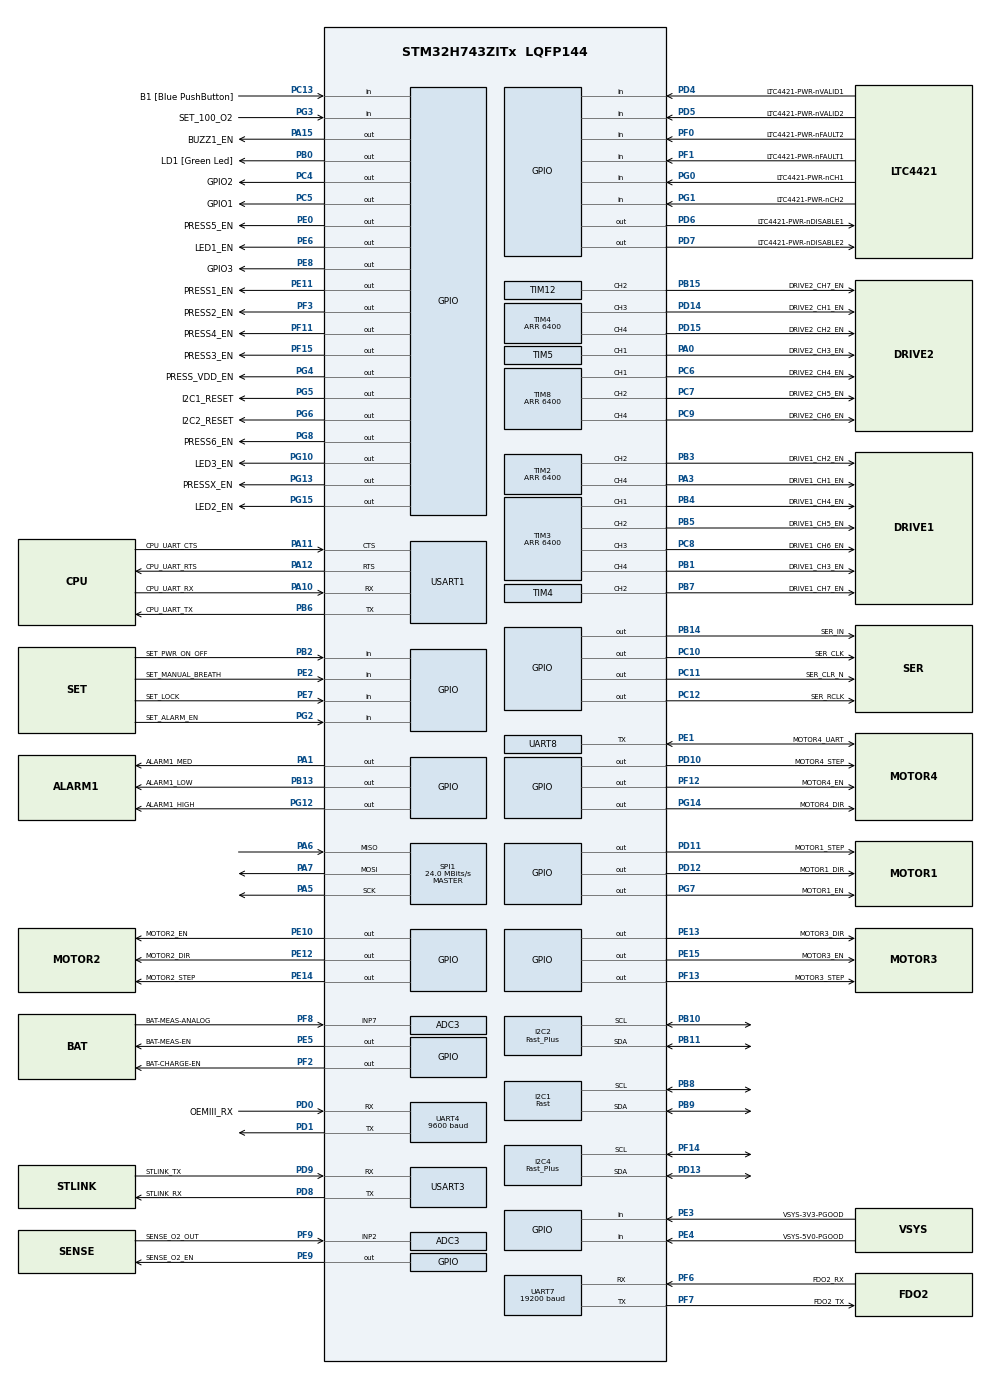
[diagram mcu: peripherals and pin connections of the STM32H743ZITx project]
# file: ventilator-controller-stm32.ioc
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ADC3.Channel-0\#ChannelRegularConversion=ADC_CHANNEL_7
ADC3.ContinuousConvMode=ENABLE
ADC3.EnableAnalogWatchDog3=false
ADC3.NbrOfConversionFlag=1
ADC3.OffsetNumber-0\#ChannelRegularConversion=ADC_OFFSET_NONE
ADC3.Overrun=ADC_OVR_DATA_OVERWRITTEN
ADC3.Rank-0\#ChannelRegularConversion=1
ADC3.SamplingTime-0\#ChannelRegularConversion=ADC_SAMPLETIME_1CYCLE_5
CRC.DefaultPolynomialUse=DEFAULT_POLYNOMIAL_DISABLE
CRC.GeneratingPolynomial=X28+X27+X26+X25+X23+X22+X20+X19+X18+X14+X13+X11+X10+X9+X8+X6+X0
CRC.InputDataInversionMode=CRC_INPUTDATA_INVERSION_BYTE
CRC.OutputDataInversionMode=CRC_OUTPUTDATA_INVERSION_ENABLE
I2C1.I2C_Speed_Mode=I2C_Fast
I2C1.Timing=0x00602173
I2C2.I2C_Speed_Mode=I2C_Fast_Plus
I2C2.Timing=0x00300B29
I2C4.I2C_Speed_Mode=I2C_Fast_Plus
I2C4.Timing=0x00300B29
Mcu.Family=STM32H7
Mcu.Name=STM32H743ZITx
Mcu.Package=LQFP144
NVIC.PriorityGroup=NVIC_PRIORITYGROUP_4
NVIC.UART4_IRQn=true\:0\:0\:false\:false\:true\:true\:true
NVIC.UART7_IRQn=true\:0\:0\:false\:false\:true\:true\:true
NVIC.USART3_IRQn=true\:0\:0\:false\:false\:true\:true\:true
PA0.GPIO_Label=DRIVE2_CH3_EN
PA0.Signal=S_TIM5_CH1
PA1.GPIO_Label=ALARM1_MED
PA1.Signal=GPIO_Output
PA10.GPIO_Label=CPU_UART_RX
PA10.Mode=Asynchronous
PA10.Signal=USART1_RX
PA11.GPIO_Label=CPU_UART_CTS
PA11.Mode=CTS_RTS
PA11.Signal=USART1_CTS
PA12.GPIO_Label=CPU_UART_RTS
PA12.Mode=CTS_RTS
PA12.Signal=USART1_RTS
PA15\ (JTDI).GPIO_Label=BUZZ1_EN
PA15\ (JTDI).Signal=GPIO_Output
PA3.GPIO_Label=DRIVE1_CH1_EN
PA3.Signal=S_TIM2_CH4
PA4.Signal=SPI1_NSS
PA5.Mode=Full_Duplex_Master
PA5.Signal=SPI1_SCK
PA6.Mode=Full_Duplex_Master
PA6.Signal=SPI1_MISO
PA7.Mode=Full_Duplex_Master
PA7.Signal=SPI1_MOSI
PA8.GPIO_Label=CPU_UART_CLK
PA8.Signal=USART1_CK
PB0.GPIO_Label=LD1 [Green Led]
PB0.Signal=GPIO_Output
PB1.GPIO_Label=DRIVE1_CH3_EN
PB1.Signal=S_TIM3_CH4
PB10.Mode=I2C
PB10.Signal=I2C2_SCL
PB11.Mode=I2C
PB11.Signal=I2C2_SDA
PB12.Signal=I2C2_SMBA
PB13.GPIO_Label=ALARM1_LOW
PB13.Signal=GPIO_Output
PB14.GPIO_Label=SER_IN
PB14.Signal=GPIO_Output
PB15.GPIO_Label=DRIVE2_CH7_EN
PB15.Signal=S_TIM12_CH2
PB2.GPIO_Label=SET_PWR_ON_OFF
PB2.Signal=GPIO_Input
PB3\ (JTDO/TRACESWO).GPIO_Label=DRIVE1_CH2_EN
PB3\ (JTDO/TRACESWO).Signal=S_TIM2_CH2
PB4\ (NJTRST).GPIO_Label=DRIVE1_CH4_EN
PB4\ (NJTRST).Signal=S_TIM3_CH1
PB5.GPIO_Label=DRIVE1_CH5_EN
PB5.Signal=S_TIM3_CH2
PB6.GPIO_Label=CPU_UART_TX
PB6.Mode=Asynchronous
PB6.Signal=USART1_TX
PB7.GPIO_Label=DRIVE1_CH7_EN
PB7.Signal=S_TIM4_CH2
PB8.Mode=I2C
PB8.Signal=I2C1_SCL
PB9.Mode=I2C
PB9.Signal=I2C1_SDA
PC10.GPIO_Label=SER_CLK
PC10.Signal=GPIO_Output
PC11.GPIO_Label=SER_CLR_N
PC11.Signal=GPIO_Output
PC12.GPIO_Label=SER_RCLK
PC12.Signal=GPIO_Output
PC13.GPIO_Label=B1 [Blue PushButton]
PC13.Signal=GPIO_Input
PC14-OSC32_IN\ (OSC32_IN).Mode=LSE-External-Oscillator
PC14-OSC32_IN\ (OSC32_IN).Signal=RCC_OSC32_IN
PC15-OSC32_OUT\ (OSC32_OUT).Mode=LSE-External-Oscillator
PC15-OSC32_OUT\ (OSC32_OUT).Signal=RCC_OSC32_OUT
PC4.GPIO_Label=GPIO2
PC4.Signal=GPIO_Output
PC5.GPIO_Label=GPIO1
PC5.Signal=GPIO_Output
PC6.GPIO_Label=DRIVE2_CH4_EN
PC6.Signal=S_TIM8_CH1
PC7.GPIO_Label=DRIVE2_CH5_EN
PC7.Signal=S_TIM8_CH2
PC8.GPIO_Label=DRIVE1_CH6_EN
PC8.Signal=S_TIM3_CH3
PC9.GPIO_Label=DRIVE2_CH6_EN
PC9.Signal=S_TIM8_CH4
PD0.GPIO_Label=OEMIII_RX
PD0.Mode=Asynchronous
PD0.Signal=UART4_RX
PD1.Mode=Asynchronous
PD1.Signal=UART4_TX
PD10.GPIO_Label=MOTOR4_STEP
PD10.Signal=GPIO_Output
PD11.GPIO_Label=MOTOR1_STEP
PD11.Signal=GPIO_Output
PD12.GPIO_Label=MOTOR1_DIR
PD12.Signal=GPIO_Output
PD13.Mode=I2C
PD13.Signal=I2C4_SDA
PD14.GPIO_Label=DRIVE2_CH1_EN
PD14.Signal=S_TIM4_CH3
PD15.GPIO_Label=DRIVE2_CH2_EN
PD15.Signal=S_TIM4_CH4
PD4.GPIO_Label=LTC4421-PWR-nVALID1
PD4.Signal=GPIO_Input
PD5.GPIO_Label=LTC4421-PWR-nVALID2
PD5.Signal=GPIO_Input
PD6.GPIO_Label=LTC4421-PWR-nDISABLE1
PD6.Signal=GPIO_Output
PD7.GPIO_Label=LTC4421-PWR-nDISABLE2
PD7.Signal=GPIO_Output
PD8.GPIO_Label=STLINK_RX
PD8.Mode=Asynchronous
PD8.Signal=USART3_TX
PD9.GPIO_Label=STLINK_TX
PD9.Mode=Asynchronous
PD9.Signal=USART3_RX
PE0.GPIO_Label=PRESS5_EN
PE0.Signal=GPIO_Output
PE1.GPIO_Label=MOTOR4_UART
PE1.Mode=Half_duplex(single_wire_mode)
PE1.Signal=UART8_TX
PE10.GPIO_Label=MOTOR2_EN
PE10.Signal=GPIO_Output
PE11.GPIO_Label=PRESS1_EN
PE11.Signal=GPIO_Output
PE12.GPIO_Label=MOTOR2_DIR
PE12.Signal=GPIO_Output
PE13.GPIO_Label=MOTOR3_DIR
PE13.Signal=GPIO_Output
PE14.GPIO_Label=MOTOR2_STEP
PE14.Signal=GPIO_Output
PE15.GPIO_Label=MOTOR3_EN
PE15.Signal=GPIO_Output
PE2.GPIO_Label=SET_MANUAL_BREATH
PE2.Signal=GPIO_Input
PE3.GPIO_Label=VSYS-3V3-PGOOD
PE3.Signal=GPIO_Input
PE4.GPIO_Label=VSYS-5V0-PGOOD
PE4.Signal=GPIO_Input
PE5.GPIO_Label=BAT-MEAS-EN
PE5.Signal=GPIO_Output
PE6.GPIO_Label=LED1_EN
PE6.Signal=GPIO_Output
PE7.GPIO_Label=SET_LOCK
PE7.Signal=GPIO_Input
PE8.GPIO_Label=GPIO3
PE8.Signal=GPIO_Output
PE9.GPIO_Label=SENSE_O2_EN
PE9.Signal=GPIO_Output
PF0.GPIO_Label=LTC4421-PWR-nFAULT2
PF0.Signal=GPIO_Input
PF1.GPIO_Label=LTC4421-PWR-nFAULT1
PF1.Signal=GPIO_Input
PF11.GPIO_Label=PRESS4_EN
PF11.Signal=GPIO_Output
PF12.GPIO_Label=MOTOR4_EN
PF12.Signal=GPIO_Output
PF13.GPIO_Label=MOTOR3_STEP
PF13.Signal=GPIO_Output
PF14.Mode=I2C
PF14.Signal=I2C4_SCL
PF15.GPIO_Label=PRESS3_EN
PF15.Signal=GPIO_Output
PF2.GPIO_Label=BAT-CHARGE-EN
PF2.Signal=GPIO_Output
PF3.GPIO_Label=PRESS2_EN
PF3.Signal=GPIO_Output
PF6.GPIO_Label=FDO2_RX
PF6.Mode=Asynchronous
PF6.Signal=UART7_RX
PF7.GPIO_Label=FDO2_TX
PF7.Mode=Asynchronous
PF7.Signal=UART7_TX
PF8.GPIO_Label=BAT-MEAS-ANALOG
PF8.Mode=IN7-Single-Ended
PF8.Signal=ADC3_INP7
PF9.GPIO_Label=SENSE_O2_OUT
PF9.Mode=IN2-Single-Ended
PF9.Signal=ADC3_INP2
PG0.GPIO_Label=LTC4421-PWR-nCH1
PG0.Signal=GPIO_Input
PG1.GPIO_Label=LTC4421-PWR-nCH2
PG1.Signal=GPIO_Input
PG10.GPIO_Label=LED3_EN
PG10.Signal=GPIO_Output
PG12.GPIO_Label=ALARM1_HIGH
PG12.Signal=GPIO_Output
PG13.GPIO_Label=PRESSX_EN
PG13.Signal=GPIO_Output
PG14.GPIO_Label=MOTOR4_DIR
PG14.Signal=GPIO_Output
PG15.GPIO_Label=LED2_EN
PG15.Signal=GPIO_Output
PG2.GPIO_Label=SET_ALARM_EN
PG2.Signal=GPIO_Input
PG3.GPIO_Label=SET_100_O2
PG3.Signal=GPIO_Input
PG4.GPIO_Label=PRESS_VDD_EN
PG4.Signal=GPIO_Output
PG5.GPIO_Label=I2C1_RESET
PG5.Signal=GPIO_Output
PG6.GPIO_Label=I2C2_RESET
PG6.Signal=GPIO_Output
PG7.GPIO_Label=MOTOR1_EN
PG7.Signal=GPIO_Output
PG8.GPIO_Label=PRESS6_EN
PG8.Signal=GPIO_Output
PH0-OSC_IN\ (PH0).Mode=HSE-External-Clock-Source
PH0-OSC_IN\ (PH0).Signal=RCC_OSC_IN
PH1-OSC_OUT\ (PH1).Signal=RCC_OSC_OUT
ProjectManager.HeapSize=0x200
ProjectManager.StackSize=0x400
ProjectManager.TargetToolchain=STM32CubeIDE
RCC.ADCFreq_Value=50666666.666666664
RCC.APB1Freq_Value=64000000
RCC.APB2Freq_Value=64000000
RCC.APB3Freq_Value=64000000
RCC.APB4Freq_Value=64000000
RCC.CortexFreq_Value=64000000
RCC.DIVM1=1
RCC.DIVM2=1
RCC.DIVN1=24
RCC.DIVN2=19
RCC.DIVP2=3
RCC.DIVQ1=4
RCC.HCLKFreq_Value=64000000
RCC.HSE_VALUE=8000000
RCC.PLLFRACN=0
RCC.PLLSourceVirtual=RCC_PLLSOURCE_HSE
RCC.SYSCLKFreq_VALUE=64000000
RCC.USBFreq_Value=48000000
SH.S_TIM12_CH2.0=TIM12_CH2,PWM Generation2 CH2
SH.S_TIM2_CH2.0=TIM2_CH2,PWM Generation2 CH2
SH.S_TIM2_CH4.0=TIM2_CH4,PWM Generation4 CH4
SH.S_TIM3_CH1.0=TIM3_CH1,PWM Generation1 CH1
SH.S_TIM3_CH2.0=TIM3_CH2,PWM Generation2 CH2
SH.S_TIM3_CH3.0=TIM3_CH3,PWM Generation3 CH3
SH.S_TIM3_CH4.0=TIM3_CH4,PWM Generation4 CH4
SH.S_TIM4_CH2.0=TIM4_CH2,PWM Generation2 CH2
SH.S_TIM4_CH3.0=TIM4_CH3,PWM Generation3 CH3
SH.S_TIM4_CH4.0=TIM4_CH4,PWM Generation4 CH4
SH.S_TIM5_CH1.0=TIM5_CH1,PWM Generation1 CH1
SH.S_TIM8_CH1.0=TIM8_CH1,PWM Generation1 CH1
SH.S_TIM8_CH2.0=TIM8_CH2,PWM Generation2 CH2
SH.S_TIM8_CH4.0=TIM8_CH4,PWM Generation4 CH4
SPI1.CalculateBaudRate=24.0 MBits/s
SPI1.Direction=SPI_DIRECTION_2LINES
SPI1.Mode=SPI_MODE_MASTER
SPI1.VirtualType=VM_MASTER
TIM12.Channel-PWM\ Generation2\ CH2=TIM_CHANNEL_2
TIM12.Period=6400
TIM2.Channel-PWM\ Generation2\ CH2=TIM_CHANNEL_2
TIM2.Channel-PWM\ Generation4\ CH4=TIM_CHANNEL_4
TIM2.Period=6400
TIM3.Channel-PWM\ Generation1\ CH1=TIM_CHANNEL_1
TIM3.Channel-PWM\ Generation2\ CH2=TIM_CHANNEL_2
TIM3.Channel-PWM\ Generation3\ CH3=TIM_CHANNEL_3
TIM3.Channel-PWM\ Generation4\ CH4=TIM_CHANNEL_4
TIM3.Period=6400
TIM4.Channel-PWM\ Generation2\ CH2=TIM_CHANNEL_2
TIM4.Channel-PWM\ Generation3\ CH3=TIM_CHANNEL_3
TIM4.Channel-PWM\ Generation4\ CH4=TIM_CHANNEL_4
TIM4.Period=6400
TIM5.Channel-PWM\ Generation1\ CH1=TIM_CHANNEL_1
TIM5.Period=6400
TIM8.Channel-PWM\ Generation1\ CH1=TIM_CHANNEL_1
TIM8.Channel-PWM\ Generation2\ CH2=TIM_CHANNEL_2
TIM8.Channel-PWM\ Generation4\ CH4=TIM_CHANNEL_4
TIM8.Period=6400
UART4.BaudRate=9600
UART7.BaudRate=19200
USART1.VirtualMode-Asynchronous=VM_ASYNC
USART3.VirtualMode-Asynchronous=VM_ASYNC
USART3.VirtualMode-Half_duplex(single_wire_mode)=VM_ASYNC
VP_CRC_VS_CRC.Mode=CRC_Activate
VP_RNG_VS_RNG.Mode=RNG_Activate
VP_TIM2_VS_ClockSourceINT.Mode=Internal
board=NUCLEO-H743ZI2

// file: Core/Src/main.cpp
/* USER CODE BEGIN Header */
/**
 * Original work Copyright 2020, STMicroelectronics
 * Modified work Copyright 2020, the Pez Globo team and the Pufferfish project
 *contributors
 *
 ******************************************************************************
 * @file           : main.cpp
 * @brief          : Main program body
 ******************************************************************************
 * @attention
 *
 * <h2><center>&copy; Copyright (c) 2020 STMicroelectronics.
 * All rights reserved.</center></h2>
 *
 * This software component is licensed by ST under BSD 3-Clause license,
 * the "License"; You may not use this file except in compliance with the
 * License. You may obtain a copy of the License at:
 *                        opensource.org/licenses/BSD-3-Clause
 *
 ******************************************************************************
 */
/* USER CODE END Header */

#include "main.h"

/* USER CODE BEGIN Includes */
#include <functional>

#include "Pufferfish/AlarmsManager.h"
#include "Pufferfish/Application/AlarmMuteService.h"
#include "Pufferfish/Application/Alarms.h"
#include "Pufferfish/Application/LogEvents.h"
#include "Pufferfish/Application/ScreenLock.h"
#include "Pufferfish/Application/States.h"
#include "Pufferfish/Application/mcu_pb.h"  // Only used for debugging
#include "Pufferfish/Driver/BreathingCircuit/AlarmLimitsService.h"
#include "Pufferfish/Driver/BreathingCircuit/Alarms.h"
#include "Pufferfish/Driver/BreathingCircuit/AlarmsService.h"
#include "Pufferfish/Driver/BreathingCircuit/ControlLoop.h"
#include "Pufferfish/Driver/BreathingCircuit/ParametersService.h"
#include "Pufferfish/Driver/BreathingCircuit/SensorAlarmsService.h"
#include "Pufferfish/Driver/BreathingCircuit/SignalSmoothing.h"
#include "Pufferfish/Driver/BreathingCircuit/Simulator.h"
#include "Pufferfish/Driver/Button/Button.h"
#include "Pufferfish/Driver/I2C/ExtendedI2CDevice.h"
#include "Pufferfish/Driver/I2C/HoneywellABP/Device.h"
#include "Pufferfish/Driver/I2C/HoneywellABP/Sensor.h"
#include "Pufferfish/Driver/I2C/LTC4015/Sensor.h"
#include "Pufferfish/Driver/I2C/SDP.h"
#include "Pufferfish/Driver/I2C/SFM3000.h"
#include "Pufferfish/Driver/I2C/SFM3019/Sensor.h"
#include "Pufferfish/Driver/I2C/TCA9548A.h"
#include "Pufferfish/Driver/Indicators/AuditoryAlarm.h"
#include "Pufferfish/Driver/Indicators/LEDAlarm.h"
#include "Pufferfish/Driver/Indicators/PulseGenerator.h"
#include "Pufferfish/Driver/Power/AlarmsService.h"
#include "Pufferfish/Driver/Power/Simulator.h"
#include "Pufferfish/Driver/Serial/Backend/AlarmsService.h"
#include "Pufferfish/Driver/Serial/Backend/UART.h"
#include "Pufferfish/Driver/Serial/FDO2/Sensor.h"
#include "Pufferfish/Driver/Serial/Nonin/Sensor.h"
#include "Pufferfish/Driver/Serial/Nonin/SensorAlarmService.h"
#include "Pufferfish/Driver/ShiftedOutput.h"
#include "Pufferfish/HAL/Endian.h"
#include "Pufferfish/HAL/STM32/HAL.h"
#include "Pufferfish/Statuses.h"
#include "Pufferfish/Util/Timeouts.h"

/* USER CODE END Includes */

ADC_HandleTypeDef hadc3;

CRC_HandleTypeDef hcrc;

I2C_HandleTypeDef hi2c1;
I2C_HandleTypeDef hi2c2;
I2C_HandleTypeDef hi2c4;

RNG_HandleTypeDef hrng;

SPI_HandleTypeDef hspi1;

TIM_HandleTypeDef htim2;
TIM_HandleTypeDef htim3;
TIM_HandleTypeDef htim4;
TIM_HandleTypeDef htim5;
TIM_HandleTypeDef htim8;
TIM_HandleTypeDef htim12;

UART_HandleTypeDef huart4;
UART_HandleTypeDef huart7;
UART_HandleTypeDef huart8;
UART_HandleTypeDef huart1;
UART_HandleTypeDef huart3;

/* USER CODE BEGIN PV */

namespace PF = Pufferfish;

// Application State
PF::Application::Store store;

// Event Logging
PF::Application::LogEventsSender log_events_sender;
PF::Application::LogEventsManager log_events_manager(log_events_sender);

// Request/Response Services
PF::Driver::BreathingCircuit::ParametersServices parameters_service;
PF::Driver::BreathingCircuit::AlarmLimitsServices alarm_limits_service;

// Breathing Circuit Simulation
PF::Driver::BreathingCircuit::Simulators simulator;

// HAL Utilities
PF::HAL::STM32::CRC32 crc32c(hcrc);
PF::HAL::STM32::Random rng(hrng);
// HAL Time
// Normally we'd call this variable "time", but it conflicts with a declaration from <ctime>,
// which is required by the Boost PFR library
PF::HAL::STM32::Time hal_time;

// Buffered UARTs
volatile Pufferfish::HAL::STM32::LargeBufferedUART backend_uart(huart3, hal_time);
volatile Pufferfish::HAL::STM32::LargeBufferedUART fdo2_uart(huart7, hal_time);
volatile Pufferfish::HAL::STM32::ReadOnlyBufferedUART nonin_oem_uart(huart4, hal_time);

// UART Serial Communication
PF::Driver::Serial::Backend::UARTBackend backend(backend_uart, crc32c, store, log_events_sender);
PF::Driver::Serial::Backend::AlarmsService backend_alarms;

// Create an object for ADC3 of AnalogInput Class
static const uint32_t adc_poll_timeout = 10;
PF::HAL::STM32::AnalogInput adc3_input(hadc3, adc_poll_timeout);

// The following lines suppress Eclipse CDT's warning about C-style casts;
// those come from STM32CubeMX-generated #define constants, which we have no
// control over

// Interface Board
PF::HAL::STM32::DigitalOutput ser_clock(
    *SER_CLK_GPIO_Port,  // @suppress("C-Style cast instead of C++ cast") // NOLINT(cppcoreguidelines-pro-type-cstyle-cast)
    SER_CLK_Pin,  // @suppress("C-Style cast instead of C++ cast")
    true);
PF::HAL::STM32::DigitalOutput ser_clear(
    *SER_CLR_N_GPIO_Port,  // @suppress("C-Style cast instead of C++ cast") // NOLINT(cppcoreguidelines-pro-type-cstyle-cast)
    SER_CLR_N_Pin,  // @suppress("C-Style cast instead of C++ cast")
    false);
PF::HAL::STM32::DigitalOutput ser_r_clock(
    *SER_RCLK_GPIO_Port,  // @suppress("C-Style cast instead of C++ cast") // NOLINT(cppcoreguidelines-pro-type-cstyle-cast)
    SER_RCLK_Pin,  // @suppress("C-Style cast instead of C++ cast")
    true);
PF::HAL::STM32::DigitalOutput ser_input(
    *SER_IN_GPIO_Port,  // @suppress("C-Style cast instead of C++ cast") // NOLINT(cppcoreguidelines-pro-type-cstyle-cast)
    SER_IN_Pin,  // @suppress("C-Style cast instead of C++ cast")
    true);

PF::HAL::STM32::DigitalOutput board_led1(
    *LD1_GPIO_Port,  // @suppress("C-Style cast instead of C++ cast") // NOLINT(cppcoreguidelines-pro-type-cstyle-cast)
    LD1_Pin);  // @suppress("C-Style cast instead of C++ cast") // NOLINT(cppcoreguidelines-pro-type-cstyle-cast)
static const uint32_t flash_period = 50;
static const uint32_t blink_period = 500;
static const uint32_t dim_period = 8;
PF::Driver::Indicators::PWMGenerator flasher(flash_period, 1);
PF::Driver::Indicators::PWMGenerator blinker(blink_period, 1);
PF::Driver::Indicators::PWMGenerator dimmer(dim_period, 1);
PF::Driver::ShiftRegister leds_reg(ser_input, ser_clock, ser_r_clock, ser_clear, hal_time);

PF::Driver::ShiftedOutput alarm_led_r(leds_reg, 0);
PF::Driver::ShiftedOutput alarm_led_g(leds_reg, 1);
PF::Driver::ShiftedOutput alarm_led_b(leds_reg, 2);
PF::Driver::ShiftedOutput led_alarm_en(leds_reg, 3);
PF::Driver::ShiftedOutput led_full_o2(leds_reg, 4);
// NOLINTNEXTLINE(readability-magic-numbers)
PF::Driver::ShiftedOutput led_manual_breath(leds_reg, 5);
// NOLINTNEXTLINE(readability-magic-numbers)
PF::Driver::ShiftedOutput led_lock(leds_reg, 6);

PF::HAL::STM32::DigitalOutput alarm_reg_high(
    *ALARM1_HIGH_GPIO_Port,  // @suppress("C-Style cast instead of C++ cast") // NOLINT(cppcoreguidelines-pro-type-cstyle-cast)
    ALARM1_HIGH_Pin);  // @suppress("C-Style cast instead of C++ cast") // NOLINT(cppcoreguidelines-pro-type-cstyle-cast)
PF::HAL::STM32::DigitalOutput alarm_reg_med(
    *ALARM1_MED_GPIO_Port,  // @suppress("C-Style cast instead of C++ cast") // NOLINT(cppcoreguidelines-pro-type-cstyle-cast)
    ALARM1_MED_Pin);  // @suppress("C-Style cast instead of C++ cast") // NOLINT(cppcoreguidelines-pro-type-cstyle-cast)
PF::HAL::STM32::DigitalOutput alarm_reg_low(
    *ALARM1_LOW_GPIO_Port,  // @suppress("C-Style cast instead of C++ cast") // NOLINT(cppcoreguidelines-pro-type-cstyle-cast)
    ALARM1_LOW_Pin);  // @suppress("C-Style cast instead of C++ cast") // NOLINT(cppcoreguidelines-pro-type-cstyle-cast)
PF::HAL::STM32::DigitalOutput alarm_buzzer(
    *BUZZ1_EN_GPIO_Port,  // @suppress("C-Style cast instead of C++ cast") // NOLINT(cppcoreguidelines-pro-type-cstyle-cast)
    BUZZ1_EN_Pin);  // @suppress("C-Style cast instead of C++ cast") // NOLINT(cppcoreguidelines-pro-type-cstyle-cast)

PF::Driver::Indicators::LEDAlarm alarm_dev_led(alarm_led_r, alarm_led_g, alarm_led_b);
PF::Driver::Indicators::AuditoryAlarm alarm_dev_sound(
    alarm_reg_high, alarm_reg_med, alarm_reg_low, alarm_buzzer);
// PF::AlarmsManager h_alarms(alarm_dev_led, alarm_dev_sound);

PF::HAL::STM32::DigitalInput button_alarm_en(
    *SET_ALARM_EN_GPIO_Port,  // @suppress("C-Style cast instead of C++ cast") // NOLINT(cppcoreguidelines-pro-type-cstyle-cast)
    SET_ALARM_EN_Pin,  // @suppress("C-Style cast instead of C++ cast")
    true);
PF::HAL::STM32::DigitalInput button_full_o2(
    *SET_100_O2_GPIO_Port,  // @suppress("C-Style cast instead of C++ cast") // NOLINT(cppcoreguidelines-pro-type-cstyle-cast)
    SET_100_O2_Pin,  // @suppress("C-Style cast instead of C++ cast")
    true);
PF::HAL::STM32::DigitalInput button_manual_breath(
    *SET_MANUAL_BREATH_GPIO_Port,  // @suppress("C-Style cast instead of C++ cast") // NOLINT(cppcoreguidelines-pro-type-cstyle-cast)
    SET_MANUAL_BREATH_Pin,  // @suppress("C-Style cast instead of C++ cast")
    true);
PF::HAL::STM32::DigitalInput button_lock(
    *SET_LOCK_GPIO_Port,  // @suppress("C-Style cast instead of C++ cast") // NOLINT(cppcoreguidelines-pro-type-cstyle-cast)
    SET_LOCK_Pin,  // @suppress("C-Style cast instead of C++ cast")
    true);
PF::HAL::STM32::DigitalInput button_power(
    *SET_PWR_ON_OFF_GPIO_Port,  // @suppress("C-Style cast instead of C++ cast") // NOLINT(cppcoreguidelines-pro-type-cstyle-cast)
    SET_PWR_ON_OFF_Pin,  // @suppress("C-Style cast instead of C++ cast")
    true);

PF::Protocols::Application::Debouncer switch_debounce;
PF::Driver::Button::Button button_membrane(button_alarm_en, switch_debounce, hal_time);

// Solenoid Valves
PF::HAL::STM32::PWM drive1_ch1(htim2, TIM_CHANNEL_4);
PF::HAL::STM32::PWM drive1_ch2(htim2, TIM_CHANNEL_2);
PF::HAL::STM32::PWM drive1_ch3(htim3, TIM_CHANNEL_4);
PF::HAL::STM32::PWM drive1_ch4(htim3, TIM_CHANNEL_1);
PF::HAL::STM32::PWM drive1_ch5(htim3, TIM_CHANNEL_2);
PF::HAL::STM32::PWM drive1_ch6(htim3, TIM_CHANNEL_3);
PF::HAL::STM32::PWM drive1_ch7(htim4, TIM_CHANNEL_2);
PF::HAL::STM32::PWM drive2_ch1(htim4, TIM_CHANNEL_3);
PF::HAL::STM32::PWM drive2_ch2(htim4, TIM_CHANNEL_4);
PF::HAL::STM32::PWM drive2_ch3(htim5, TIM_CHANNEL_1);
PF::HAL::STM32::PWM drive2_ch4(htim8, TIM_CHANNEL_1);
PF::HAL::STM32::PWM drive2_ch5(htim8, TIM_CHANNEL_2);
PF::HAL::STM32::PWM drive2_ch6(htim8, TIM_CHANNEL_4);
PF::HAL::STM32::PWM drive2_ch7(htim12, TIM_CHANNEL_2);

// Base I2C Devices
// Note: I2C1 is marked I2C2 in the control board v1.0 schematic, and vice versa
/*PF::HAL::STM32::I2CDevice i2c_hal_mux1(hi2c2, PF::Driver::I2C::TCA9548A::default_i2c_addr);
PF::HAL::STM32::I2CDevice i2c_hal_mux2(hi2c1, PF::Driver::I2C::TCA9548A::default_i2c_addr);

PF::HAL::STM32::I2CDevice i2c_hal_press1(hi2c1, PF::Driver::I2C::abpxxxx001pg2a3.i2c_addr);
PF::HAL::STM32::I2CDevice i2c_hal_press2(hi2c1, PF::Driver::I2C::abpxxxx001pg2a3.i2c_addr);
PF::HAL::STM32::I2CDevice i2c_hal_press3(hi2c1, PF::Driver::I2C::abpxxxx001pg2a3.i2c_addr);
PF::HAL::STM32::I2CDevice i2c_hal_press7(hi2c1, PF::Driver::I2C::abpxxxx030pg2a3.i2c_addr);
PF::HAL::STM32::I2CDevice i2c_hal_press8(hi2c1, PF::Driver::I2C::abpxxxx030pg2a3.i2c_addr);
PF::HAL::STM32::I2CDevice i2c_hal_press9(hi2c1, PF::Driver::I2C::abpxxxx001pg2a3.i2c_addr);
PF::HAL::STM32::I2CDevice i2c_hal_press13(hi2c2, PF::Driver::I2C::SDPSensor::sdp8xx_i2c_addr);
PF::HAL::STM32::I2CDevice i2c_hal_press14(hi2c2, PF::Driver::I2C::SDPSensor::sdp3x_i2c_addr);
PF::HAL::STM32::I2CDevice i2c_hal_press15(hi2c2, PF::Driver::I2C::SDPSensor::sdp3x_i2c_addr);
PF::HAL::STM32::I2CDevice i2c_hal_press16(hi2c2, PF::Driver::I2C::SFM3000::default_i2c_addr);
PF::HAL::STM32::I2CDevice i2c_hal_press17(hi2c2, PF::Driver::I2C::SDPSensor::sdp3x_i2c_addr);
PF::HAL::STM32::I2CDevice i2c_hal_press18(hi2c2, PF::Driver::I2C::SDPSensor::sdp3x_i2c_addr);*/

PF::HAL::STM32::I2CDevice i2c1_hal_global(hi2c1, 0x00);
PF::HAL::STM32::I2CDevice i2c2_hal_global(hi2c2, 0x00);
PF::HAL::STM32::I2CDevice i2c4_hal_global(hi2c4, 0x00);
PF::HAL::STM32::I2CDevice i2c_hal_abp(
    hi2c1, PF::Driver::I2C::HoneywellABP::abpxxxx001pg2a3.i2c_addr);
PF::HAL::STM32::I2CDevice i2c_hal_ltc4015(hi2c1, PF::Driver::I2C::LTC4015::device_addr);
PF::HAL::STM32::I2CDevice i2c_hal_sfm3019_air(hi2c2, PF::Driver::I2C::SFM3019::default_i2c_addr);
PF::HAL::STM32::I2CDevice i2c_hal_sfm3019_o2(hi2c4, PF::Driver::I2C::SFM3019::default_i2c_addr);
/*
// I2C Mux
PF::Driver::I2C::TCA9548A i2c_mux1(i2c_hal_mux1);
PF::Driver::I2C::TCA9548A i2c_mux2(i2c_hal_mux2);

// Extended I2C Device
PF::Driver::I2C::ExtendedI2CDevice i2c_ext_press1(i2c_hal_press1, i2c_mux2, 0);
PF::Driver::I2C::ExtendedI2CDevice i2c_ext_press2(i2c_hal_press2, i2c_mux2, 2);
PF::Driver::I2C::ExtendedI2CDevice i2c_ext_press3(i2c_hal_press3, i2c_mux2, 4);
PF::Driver::I2C::ExtendedI2CDevice i2c_ext_press7(i2c_hal_press7, i2c_mux2, 1);
PF::Driver::I2C::ExtendedI2CDevice i2c_ext_press8(i2c_hal_press8, i2c_mux2, 3);
// NOLINTNEXTLINE(readability-magic-numbers)
PF::Driver::I2C::ExtendedI2CDevice i2c_ext_press9(i2c_hal_press9, i2c_mux2, 5);

PF::Driver::I2C::ExtendedI2CDevice i2c_ext_press13(i2c_hal_press13, i2c_mux1, 0);
PF::Driver::I2C::ExtendedI2CDevice i2c_ext_press14(i2c_hal_press14, i2c_mux1, 2);
PF::Driver::I2C::ExtendedI2CDevice i2c_ext_press15(i2c_hal_press15, i2c_mux1, 4);
PF::Driver::I2C::ExtendedI2CDevice i2c_ext_press16(i2c_hal_press16, i2c_mux1, 1);
PF::Driver::I2C::ExtendedI2CDevice i2c_ext_press17(i2c_hal_press17, i2c_mux1, 3);
PF::Driver::I2C::ExtendedI2CDevice i2c_ext_press18(
    i2c_hal_press18,
    i2c_mux1,
    // NOLINTNEXTLINE(readability-magic-numbers)
    5);

// Actual usable sensor
PF::Driver::I2C::HoneywellABP i2c_press1(i2c_ext_press1, PF::Driver::I2C::abpxxxx001pg2a3);
PF::Driver::I2C::HoneywellABP i2c_press2(i2c_ext_press2, PF::Driver::I2C::abpxxxx001pg2a3);
PF::Driver::I2C::HoneywellABP i2c_press3(i2c_ext_press3, PF::Driver::I2C::abpxxxx001pg2a3);
PF::Driver::I2C::HoneywellABP i2c_press7(i2c_ext_press7, PF::Driver::I2C::abpxxxx030pg2a3);
PF::Driver::I2C::HoneywellABP i2c_press8(i2c_ext_press8, PF::Driver::I2C::abpxxxx030pg2a3);
PF::Driver::I2C::HoneywellABP i2c_press9(i2c_ext_press9, PF::Driver::I2C::abpxxxx001pg2a3);
PF::Driver::I2C::SDPSensor i2c_press13(i2c_ext_press13);
PF::Driver::I2C::SDPSensor i2c_press14(i2c_ext_press14);
PF::Driver::I2C::SDPSensor i2c_press15(i2c_ext_press15);
PF::Driver::I2C::SFM3000 i2c_press16(i2c_ext_press16);
PF::Driver::I2C::SDPSensor i2c_press17(i2c_ext_press17);
PF::Driver::I2C::SDPSensor i2c_press18(i2c_ext_press18);
*/

// HoneyWell ABP
PF::Driver::I2C::HoneywellABP::Device abp_dev(
    i2c_hal_abp, PF::Driver::I2C::HoneywellABP::abpxxxx001pg2a3);
PF::Driver::I2C::HoneywellABP::Sensor abp(abp_dev, hal_time);

// SFM3019

PF::Driver::I2C::SFM3019::Device sfm3019_dev_air(
    i2c_hal_sfm3019_air, i2c2_hal_global, PF::Driver::I2C::SFM3019::GasType::air);
PF::Driver::I2C::SFM3019::Sensor sfm3019_air(sfm3019_dev_air, true, hal_time);
PF::Driver::I2C::SFM3019::Device sfm3019_dev_o2(
    i2c_hal_sfm3019_o2, i2c4_hal_global, PF::Driver::I2C::SFM3019::GasType::o2);
PF::Driver::I2C::SFM3019::Sensor sfm3019_o2(sfm3019_dev_o2, true, hal_time);

// FDO2
PF::Driver::Serial::FDO2::Device fdo2_dev(fdo2_uart);
PF::Driver::Serial::FDO2::Sensor fdo2(fdo2_dev, hal_time);

// Nonin OEM III
PF::Driver::Serial::Nonin::Device nonin_oem_dev(nonin_oem_uart);
PF::Driver::Serial::Nonin::Sensor nonin_oem(nonin_oem_dev, hal_time);

// LTC4015
PF::Driver::I2C::LTC4015::Device ltc4015_dev(i2c_hal_ltc4015);
PF::Driver::I2C::LTC4015::Sensor ltc4015(ltc4015_dev);

// Power
PF::Driver::Power::Simulator power_simulator;

// Initializables
auto initializables =
    PF::Driver::make_initializables(sfm3019_air, sfm3019_o2, abp, fdo2, nonin_oem, ltc4015);

/*
// Test list
// NOLINTNEXTLINE(readability-magic-numbers)
auto i2c_test_list = PF::Util::make_array<PF::Driver::Testable *>(
     &i2c_mux1,
     &i2c_mux2,
     &i2c_press1,
     &i2c_press2,
     &i2c_press3,
     &i2c_press7,
     &i2c_press8,
     &i2c_press9,
     &i2c_press13,
     &i2c_press14,
     &i2c_press15,
     &i2c_press16,
     &i2c_press17,
     &i2c_press18);
*/

int interface_test_state = 0;
int interface_test_millis = 0;

// Alarms
PF::Application::AlarmsManager alarms_manager(
    log_events_manager,
    PF::Driver::BreathingCircuit::debouncers,
    PF::Driver::BreathingCircuit::init_waiters);
PF::Application::AlarmMuteService alarm_mute;
PF::Driver::BreathingCircuit::AlarmsServices breathing_circuit_alarms;
PF::Driver::Power::AlarmsService power_alarms;

// Breathing Circuit Control
PF::Driver::BreathingCircuit::HFNCControlLoop hfnc(
    store.parameters(),
    store.sensor_measurements_raw(),
    sfm3019_air,
    sfm3019_o2,
    drive1_ch1,
    drive1_ch2);

// Signal processing
PF::Driver::BreathingCircuit::SensorMeasurementsSmoothers sensor_smoothers;

/* USER CODE END PV */

void SystemClock_Config(void);
static void MX_GPIO_Init(void);
static void MX_SPI1_Init(void);
static void MX_I2C1_Init(void);
static void MX_UART4_Init(void);
static void MX_ADC3_Init(void);
static void MX_CRC_Init(void);
static void MX_I2C2_Init(void);
static void MX_TIM2_Init(void);
static void MX_UART7_Init(void);
static void MX_UART8_Init(void);
static void MX_USART1_UART_Init(void);
static void MX_USART3_UART_Init(void);
static void MX_I2C4_Init(void);
static void MX_TIM3_Init(void);
static void MX_TIM4_Init(void);
static void MX_TIM5_Init(void);
static void MX_TIM8_Init(void);
static void MX_TIM12_Init(void);
static void MX_RNG_Init(void);

/* USER CODE BEGIN 0 */
void initialize_states() {
  // Parameters
  PF::Application::Parameters parameters{};
  PF::Application::StateSegment parameters_request{};
  PF::Driver::BreathingCircuit::make_state_initializers(parameters_request, parameters);
  store.parameters() = parameters;
  store.input(parameters_request, true);

  // Alarm Limits
  PF::Application::AlarmLimits alarm_limits{};
  PF::Application::StateSegment alarm_limits_request{};
  PF::Driver::BreathingCircuit::make_state_initializers(alarm_limits_request, alarm_limits);
  store.alarm_limits() = alarm_limits;
  store.input(alarm_limits_request, true);

  // Alarm Mute
  PF::Application::AlarmMute alarm_mute{};
  PF::Application::StateSegment alarm_mute_request{};
  PF::Application::make_state_initializers(alarm_mute_request, alarm_mute);
  store.alarm_mute() = alarm_mute;
  store.input(alarm_mute_request, true);
}

void interface_test_loop() {
  // get state of buttons
  bool l_alarm_en = button_alarm_en.read();
  bool l_o2 = button_full_o2.read();
  bool l_manual = button_manual_breath.read();
  bool l_lock = button_lock.read();
  // bool l_power = button_power.read();

  // simply write back
  led_alarm_en.write(l_alarm_en);
  led_full_o2.write(l_o2);
  led_manual_breath.write(l_manual);
  led_lock.write(l_lock);

  // cycle though alarms
  //  if (!l_power) {
  //    hAlarms.clearAll();
  //  } else if (hal_time.millis() - interface_test_millis > 100) {
  //    hAlarms.add(PF::AlarmStatus::highPriority);
  //    interface_test_millis = hal_time.millis();
  //    if (interface_test_state) {
  //      interface_test_state--;
  //      hAlarms.add(static_cast<PF::AlarmStatus>(interface_test_state));
  //    } else {
  //      interface_test_state = static_cast<int>(PF::AlarmStatus::noAlarm);
  //      hAlarms.clearAll();
  //    }
  //  }
}
/* USER CODE END 0 */

int main(void)
{
  /* USER CODE BEGIN 1 */

  /*
  // FIXME: Added for testing
  // Local variable to read ADC3 input
  uint32_t adc3_data = 0;

  PF::Driver::Button::EdgeState state;
  bool mem_buttonstate = false;

  static const uint32_t blink_low_delay = 5;
  static const uint32_t loop_delay = 50;
  */

  /* USER CODE END 1 */

  /* MCU Configuration--------------------------------------------------------*/

  /* Reset of all peripherals, Initializes the Flash interface and the Systick. */
  HAL_Init();

  /* Configure the system clock */
  SystemClock_Config();

  /* Initialize all configured peripherals */
  MX_GPIO_Init();
  MX_SPI1_Init();
  MX_I2C1_Init();
  MX_UART4_Init();
  MX_ADC3_Init();
  MX_CRC_Init();
  MX_I2C2_Init();
  MX_TIM2_Init();
  MX_UART7_Init();
  MX_UART8_Init();
  MX_USART1_UART_Init();
  MX_USART3_UART_Init();
  MX_I2C4_Init();
  MX_TIM3_Init();
  MX_TIM4_Init();
  MX_TIM5_Init();
  MX_TIM8_Init();
  MX_TIM12_Init();
  MX_RNG_Init();
  /* USER CODE BEGIN 2 */
  // Time
  PF::HAL::STM32::Time::micros_delay_init();

  /*
  interface_test_millis = hal_time.millis();

  // ADCs
  adc3_input.start();
  */

  // HAL utilities
  rng.setup();

  // UARTs
  backend_uart.setup_irq();
  fdo2_uart.setup_irq();
  nonin_oem_uart.setup_irq();

  // Hardware PWMs
  drive1_ch1.start();
  drive1_ch1.set_duty_cycle(0);
  drive1_ch2.start();
  drive1_ch2.set_duty_cycle(0);

  // Software PWMs
  blinker.start(hal_time.millis());
  flasher.start(hal_time.millis());
  dimmer.start(hal_time.millis());

  // Request/response states
  initialize_states();

  // Log events sender
  uint32_t session_id = 0;
  rng.generate(session_id);
  log_events_sender.setup(session_id);
  rng.generate(session_id);
  alarm_mute.setup(session_id);

  /* USER CODE END 2 */

  /* Infinite loop */
  /* USER CODE BEGIN WHILE */
  // Setup
  static const uint32_t setup_indicator_duration = 2000;
  PF::Util::MsTimer setup_indicator_timer(setup_indicator_duration);

  board_led1.write(true);
  while (true) {
    initializables.setup();
    if (initializables.setup_failed()) {
      setup_indicator_timer.reset(hal_time.millis());
      // Flash the LED rapidly to indicate failure
      while (setup_indicator_timer.within_timeout(hal_time.millis())) {
        flasher.input(hal_time.millis());
        board_led1.write(flasher.output());
      }
    } else if (initializables.setup_in_progress()) {
      board_led1.write(true);
    } else {  // All are done with setup and ok
      break;
    }
  }

  // Blink the LED somewhat slowly to indicate success
  setup_indicator_timer.reset(hal_time.millis());
  while (setup_indicator_timer.within_timeout(hal_time.millis())) {
    blinker.input(hal_time.millis());
    board_led1.write(blinker.output());
  }
  board_led1.write(false);

  // Configure the simulators
  PF::Driver::Serial::Nonin::SensorConnections sensor_connections{};
  PF::Driver::BreathingCircuit::SensorStates breathing_circuit_sensor_states{};
  uint32_t discard_i = 0;
  float discard_f = 0;
  breathing_circuit_sensor_states.sfm3019_air =
      sfm3019_air.output(discard_f) == PF::InitializableState::ok;
  breathing_circuit_sensor_states.sfm3019_o2 =
      sfm3019_o2.output(discard_f) == PF::InitializableState::ok;
  breathing_circuit_sensor_states.fdo2 = fdo2.output(discard_i) == PF::InitializableState::ok;
  bool ltc4015_status = ltc4015.output(store.mcu_power_status()) == PF::InitializableState::ok;
  // Reset nonin timer
  nonin_oem.post_setup_reset();
  breathing_circuit_sensor_states.nonin_oem =
      nonin_oem.output(sensor_connections, discard_f, discard_f) == PF::InitializableState::ok;

  // Normal loop
  while (true) {
    uint32_t current_time = hal_time.millis();

    // Software PWM signals
    flasher.input(hal_time.millis());
    blinker.input(hal_time.millis());
    dimmer.input(hal_time.millis());

    // Clock updates
    log_events_manager.update_time(current_time);
    alarms_manager.update_time(current_time);

    // Request/response services update
    parameters_service.transform(
        store.parameters_request(),
        store.has_parameters_request(),
        store.parameters(),
        log_events_manager,
        alarms_manager);
    alarm_limits_service.transform(
        store.parameters(),
        store.alarm_limits_request(),
        store.has_parameters_request() && store.has_alarm_limits_request(),
        store.alarm_limits(),
        log_events_manager);

    // Independent Sensors
    fdo2.output(hfnc.sensor_vars().po2);
    auto nonin_status = nonin_oem.output(
        sensor_connections,
        store.sensor_measurements_raw().spo2,
        store.sensor_measurements_raw().hr);
    PF::Driver::Serial::Nonin::SensorAlarmsService::transform(
        nonin_status, sensor_connections, alarms_manager);
    // *temporary* should be used in the breathing circuit
    abp.output(hfnc.sensor_vars().p_out_above_atm);

    // Breathing Circuit Sensor Simulator
    simulator.transform(
        current_time,
        store.parameters(),
        hfnc.sensor_vars(),
        breathing_circuit_sensor_states,
        store.sensor_measurements_raw(),
        store.cycle_measurements());

    // Breathing Circuit Control Loop
    hfnc.update(current_time);
    sensor_smoothers.transform(
        current_time, store.sensor_measurements_raw(), store.sensor_measurements_filtered());
    breathing_circuit_alarms.transform(
        store.parameters(),
        store.alarm_limits(),
        store.sensor_measurements_filtered(),
        alarms_manager);

    // Breathing Circuit Sensor Alarms
    PF::Driver::BreathingCircuit::SensorAlarmsService::transform(
        hfnc.sensor_connections(), alarms_manager);

    // Power management
    if (!ltc4015_status) {
      power_simulator.transform(current_time, store.mcu_power_status());
    } else {
      ltc4015.output(store.mcu_power_status());
    }

    power_alarms.transform(store.mcu_power_status(), alarms_manager);

    // Screen lock
    PF::Application::ScreenLock::transform(store.screen_status_request(), store.screen_status());

    // Indicators for debugging
    /*static constexpr float valve_opening_indicator_threshold = 0.00001;
    if (hfnc.actuator_vars().valve_air_opening > valve_opening_indicator_threshold) {
      board_led1.write(dimmer.output());
    } else {
      board_led1.write(false);
    }*/
    /*if (hfnc.sensor_vars().flow_o2 > 1 || hfnc.sensor_vars().flow_air > 1) {
      board_led1.write(true);
    } else if (hfnc.sensor_vars().flow_o2 < -1 || hfnc.sensor_vars().flow_air < -1) {
      board_led1.write(dimmer.output());
    } else {
      board_led1.write(false);
    }*/

    // Alarms
    alarms_manager.transform(store.active_log_events());
    // TODO(lietk12): allow toggling alarm mute state with the hardware button, but only when
    // both the backend and frontend are connected. This should use the
    // alarm_mute.transform(current_time, bool, ...) method.
    alarm_mute.transform(
        current_time, store.alarm_mute_request(), store.alarm_mute(), log_events_manager);
    if (!store.backend_connected()) {
      alarm_mute.transform(
          current_time,
          false,
          PF::Application::AlarmMuteSource_mcu_backend_loss,
          store.alarm_mute(),
          log_events_manager);
    } else if (!store.backend_connections().has_mcu) {
      // The MCU isn't able to send any data to the backend but the backend is able to send
      // data to the MCU, so the MCU should also cancel any active alarm mute
      alarm_mute.transform(
          current_time,
          false,
          PF::Application::AlarmMuteSource_backend_mcu_loss,
          store.alarm_mute(),
          log_events_manager);
    } else if (!store.backend_connections().has_frontend) {
      alarm_mute.transform(
          current_time,
          false,
          PF::Application::AlarmMuteSource_backend_frontend_loss,
          store.alarm_mute(),
          log_events_manager);
    }
    if (store.active_log_events().id_count > 0 && !store.alarm_mute().active) {
      board_led1.write(true);
    } else {
      blinker.input(current_time);
      board_led1.write(blinker.output());
    }

    // Backend Communication Protocol
    backend.receive();
    backend.update_clock(current_time);
    backend.send();
    store.backend_connected() = backend.connected();
    backend_alarms.transform(store.backend_connected(), alarms_manager, log_events_manager);

    /*
    PF::AlarmManagerStatus stat = h_alarms.update(hal_time.millis());
    if (stat != PF::AlarmManagerStatus::ok) {
      Error_Handler();
    }

    board_led1.write(false);
    hal_time.delay(blink_low_delay);
    board_led1.write(true);
    //interface_test_loop();
    //leds_reg.update();
    */

    /* USER CODE END WHILE */

  }
}

void SystemClock_Config(void)
{
  RCC_OscInitTypeDef RCC_OscInitStruct = {0};
  RCC_ClkInitTypeDef RCC_ClkInitStruct = {0};
  RCC_PeriphCLKInitTypeDef PeriphClkInitStruct = {0};

  /** Supply configuration update enable
  */
  HAL_PWREx_ConfigSupply(PWR_LDO_SUPPLY);
  /** Configure the main internal regulator output voltage
  */
  __HAL_PWR_VOLTAGESCALING_CONFIG(PWR_REGULATOR_VOLTAGE_SCALE3);

  while(!__HAL_PWR_GET_FLAG(PWR_FLAG_VOSRDY)) {}
  /** Macro to configure the PLL clock source
  */
  __HAL_RCC_PLL_PLLSOURCE_CONFIG(RCC_PLLSOURCE_HSE);
  /** Initializes the CPU, AHB and APB busses clocks
  */
  RCC_OscInitStruct.OscillatorType = RCC_OSCILLATORTYPE_HSI48|RCC_OSCILLATORTYPE_HSI
                              |RCC_OSCILLATORTYPE_HSE;
  RCC_OscInitStruct.HSEState = RCC_HSE_BYPASS;
  RCC_OscInitStruct.HSIState = RCC_HSI_DIV1;
  RCC_OscInitStruct.HSICalibrationValue = RCC_HSICALIBRATION_DEFAULT;
  RCC_OscInitStruct.HSI48State = RCC_HSI48_ON;
  RCC_OscInitStruct.PLL.PLLState = RCC_PLL_ON;
  RCC_OscInitStruct.PLL.PLLSource = RCC_PLLSOURCE_HSE;
  RCC_OscInitStruct.PLL.PLLM = 1;
  RCC_OscInitStruct.PLL.PLLN = 24;
  RCC_OscInitStruct.PLL.PLLP = 2;
  RCC_OscInitStruct.PLL.PLLQ = 4;
  RCC_OscInitStruct.PLL.PLLR = 2;
  RCC_OscInitStruct.PLL.PLLRGE = RCC_PLL1VCIRANGE_3;
  RCC_OscInitStruct.PLL.PLLVCOSEL = RCC_PLL1VCOWIDE;
  RCC_OscInitStruct.PLL.PLLFRACN = 0;
  if (HAL_RCC_OscConfig(&RCC_OscInitStruct) != HAL_OK)
  {
    Error_Handler();
  }
  /** Initializes the CPU, AHB and APB busses clocks
  */
  RCC_ClkInitStruct.ClockType = RCC_CLOCKTYPE_HCLK|RCC_CLOCKTYPE_SYSCLK
                              |RCC_CLOCKTYPE_PCLK1|RCC_CLOCKTYPE_PCLK2
                              |RCC_CLOCKTYPE_D3PCLK1|RCC_CLOCKTYPE_D1PCLK1;
  RCC_ClkInitStruct.SYSCLKSource = RCC_SYSCLKSOURCE_HSI;
  RCC_ClkInitStruct.SYSCLKDivider = RCC_SYSCLK_DIV1;
  RCC_ClkInitStruct.AHBCLKDivider = RCC_HCLK_DIV1;
  RCC_ClkInitStruct.APB3CLKDivider = RCC_APB3_DIV1;
  RCC_ClkInitStruct.APB1CLKDivider = RCC_APB1_DIV1;
  RCC_ClkInitStruct.APB2CLKDivider = RCC_APB2_DIV1;
  RCC_ClkInitStruct.APB4CLKDivider = RCC_APB4_DIV1;

  if (HAL_RCC_ClockConfig(&RCC_ClkInitStruct, FLASH_LATENCY_0) != HAL_OK)
  {
    Error_Handler();
  }
  PeriphClkInitStruct.PeriphClockSelection = RCC_PERIPHCLK_USART3|RCC_PERIPHCLK_UART4
                              |RCC_PERIPHCLK_UART7|RCC_PERIPHCLK_USART1
                              |RCC_PERIPHCLK_UART8|RCC_PERIPHCLK_RNG
                              |RCC_PERIPHCLK_SPI1|RCC_PERIPHCLK_I2C2
                              |RCC_PERIPHCLK_ADC|RCC_PERIPHCLK_I2C1
                              |RCC_PERIPHCLK_I2C4;
  PeriphClkInitStruct.PLL2.PLL2M = 1;
  PeriphClkInitStruct.PLL2.PLL2N = 19;
  PeriphClkInitStruct.PLL2.PLL2P = 3;
  PeriphClkInitStruct.PLL2.PLL2Q = 2;
  PeriphClkInitStruct.PLL2.PLL2R = 2;
  PeriphClkInitStruct.PLL2.PLL2RGE = RCC_PLL2VCIRANGE_3;
  PeriphClkInitStruct.PLL2.PLL2VCOSEL = RCC_PLL2VCOMEDIUM;
  PeriphClkInitStruct.PLL2.PLL2FRACN = 0;
  PeriphClkInitStruct.Spi123ClockSelection = RCC_SPI123CLKSOURCE_PLL;
  PeriphClkInitStruct.Usart234578ClockSelection = RCC_USART234578CLKSOURCE_D2PCLK1;
  PeriphClkInitStruct.Usart16ClockSelection = RCC_USART16CLKSOURCE_D2PCLK2;
  PeriphClkInitStruct.RngClockSelection = RCC_RNGCLKSOURCE_HSI48;
  PeriphClkInitStruct.I2c123ClockSelection = RCC_I2C123CLKSOURCE_D2PCLK1;
  PeriphClkInitStruct.I2c4ClockSelection = RCC_I2C4CLKSOURCE_D3PCLK1;
  PeriphClkInitStruct.AdcClockSelection = RCC_ADCCLKSOURCE_PLL2;
  if (HAL_RCCEx_PeriphCLKConfig(&PeriphClkInitStruct) != HAL_OK)
  {
    Error_Handler();
  }
}

static void MX_ADC3_Init(void)
{

  ADC_ChannelConfTypeDef sConfig = {0};

  /** Common config
  */
  hadc3.Instance = ADC3;
  hadc3.Init.ClockPrescaler = ADC_CLOCK_ASYNC_DIV1;
  hadc3.Init.Resolution = ADC_RESOLUTION_16B;
  hadc3.Init.ScanConvMode = ADC_SCAN_DISABLE;
  hadc3.Init.EOCSelection = ADC_EOC_SINGLE_CONV;
  hadc3.Init.LowPowerAutoWait = DISABLE;
  hadc3.Init.ContinuousConvMode = ENABLE;
  hadc3.Init.NbrOfConversion = 1;
  hadc3.Init.DiscontinuousConvMode = DISABLE;
  hadc3.Init.ExternalTrigConv = ADC_SOFTWARE_START;
  hadc3.Init.ExternalTrigConvEdge = ADC_EXTERNALTRIGCONVEDGE_NONE;
  hadc3.Init.ConversionDataManagement = ADC_CONVERSIONDATA_DR;
  hadc3.Init.Overrun = ADC_OVR_DATA_OVERWRITTEN;
  hadc3.Init.LeftBitShift = ADC_LEFTBITSHIFT_NONE;
  hadc3.Init.OversamplingMode = DISABLE;
  if (HAL_ADC_Init(&hadc3) != HAL_OK)
  {
    Error_Handler();
  }
  /** Configure Regular Channel
  */
  sConfig.Channel = ADC_CHANNEL_7;
  sConfig.Rank = ADC_REGULAR_RANK_1;
  sConfig.SamplingTime = ADC_SAMPLETIME_1CYCLE_5;
  sConfig.SingleDiff = ADC_SINGLE_ENDED;
  sConfig.OffsetNumber = ADC_OFFSET_NONE;
  sConfig.Offset = 0;
  if (HAL_ADC_ConfigChannel(&hadc3, &sConfig) != HAL_OK)
  {
    Error_Handler();
  }

}

static void MX_CRC_Init(void)
{

  hcrc.Instance = CRC;
  hcrc.Init.DefaultPolynomialUse = DEFAULT_POLYNOMIAL_DISABLE;
  hcrc.Init.DefaultInitValueUse = DEFAULT_INIT_VALUE_ENABLE;
  hcrc.Init.GeneratingPolynomial = 517762881;
  hcrc.Init.CRCLength = CRC_POLYLENGTH_32B;
  hcrc.Init.InputDataInversionMode = CRC_INPUTDATA_INVERSION_BYTE;
  hcrc.Init.OutputDataInversionMode = CRC_OUTPUTDATA_INVERSION_ENABLE;
  hcrc.InputDataFormat = CRC_INPUTDATA_FORMAT_BYTES;
  if (HAL_CRC_Init(&hcrc) != HAL_OK)
  {
    Error_Handler();
  }

}

static void MX_I2C1_Init(void)
{

  hi2c1.Instance = I2C1;
  hi2c1.Init.Timing = 0x00602173;
  hi2c1.Init.OwnAddress1 = 0;
  hi2c1.Init.AddressingMode = I2C_ADDRESSINGMODE_7BIT;
  hi2c1.Init.DualAddressMode = I2C_DUALADDRESS_DISABLE;
  hi2c1.Init.OwnAddress2 = 0;
  hi2c1.Init.OwnAddress2Masks = I2C_OA2_NOMASK;
  hi2c1.Init.GeneralCallMode = I2C_GENERALCALL_DISABLE;
  hi2c1.Init.NoStretchMode = I2C_NOSTRETCH_DISABLE;
  if (HAL_I2C_Init(&hi2c1) != HAL_OK)
  {
    Error_Handler();
  }
  /** Configure Analogue filter
  */
  if (HAL_I2CEx_ConfigAnalogFilter(&hi2c1, I2C_ANALOGFILTER_ENABLE) != HAL_OK)
  {
    Error_Handler();
  }
  /** Configure Digital filter
  */
  if (HAL_I2CEx_ConfigDigitalFilter(&hi2c1, 0) != HAL_OK)
  {
    Error_Handler();
  }

}

static void MX_I2C2_Init(void)
{

  hi2c2.Instance = I2C2;
  hi2c2.Init.Timing = 0x00300B29;
  hi2c2.Init.OwnAddress1 = 0;
  hi2c2.Init.AddressingMode = I2C_ADDRESSINGMODE_7BIT;
  hi2c2.Init.DualAddressMode = I2C_DUALADDRESS_DISABLE;
  hi2c2.Init.OwnAddress2 = 0;
  hi2c2.Init.OwnAddress2Masks = I2C_OA2_NOMASK;
  hi2c2.Init.GeneralCallMode = I2C_GENERALCALL_DISABLE;
  hi2c2.Init.NoStretchMode = I2C_NOSTRETCH_DISABLE;
  if (HAL_I2C_Init(&hi2c2) != HAL_OK)
  {
    Error_Handler();
  }
  /** Configure Analogue filter
  */
  if (HAL_I2CEx_ConfigAnalogFilter(&hi2c2, I2C_ANALOGFILTER_ENABLE) != HAL_OK)
  {
    Error_Handler();
  }
  /** Configure Digital filter
  */
  if (HAL_I2CEx_ConfigDigitalFilter(&hi2c2, 0) != HAL_OK)
  {
    Error_Handler();
  }
  /** I2C Enable Fast Mode Plus
  */
  HAL_I2CEx_EnableFastModePlus(I2C_FASTMODEPLUS_I2C2);

}

static void MX_I2C4_Init(void)
{

  hi2c4.Instance = I2C4;
  hi2c4.Init.Timing = 0x00300B29;
  hi2c4.Init.OwnAddress1 = 0;
  hi2c4.Init.AddressingMode = I2C_ADDRESSINGMODE_7BIT;
  hi2c4.Init.DualAddressMode = I2C_DUALADDRESS_DISABLE;
  hi2c4.Init.OwnAddress2 = 0;
  hi2c4.Init.OwnAddress2Masks = I2C_OA2_NOMASK;
  hi2c4.Init.GeneralCallMode = I2C_GENERALCALL_DISABLE;
  hi2c4.Init.NoStretchMode = I2C_NOSTRETCH_DISABLE;
  if (HAL_I2C_Init(&hi2c4) != HAL_OK)
  {
    Error_Handler();
  }
  /** Configure Analogue filter
  */
  if (HAL_I2CEx_ConfigAnalogFilter(&hi2c4, I2C_ANALOGFILTER_ENABLE) != HAL_OK)
  {
    Error_Handler();
  }
  /** Configure Digital filter
  */
  if (HAL_I2CEx_ConfigDigitalFilter(&hi2c4, 0) != HAL_OK)
  {
    Error_Handler();
  }
  /** I2C Enable Fast Mode Plus
  */
  HAL_I2CEx_EnableFastModePlus(I2C_FASTMODEPLUS_I2C4);

}

static void MX_RNG_Init(void)
{

  hrng.Instance = RNG;
  hrng.Init.ClockErrorDetection = RNG_CED_ENABLE;
  if (HAL_RNG_Init(&hrng) != HAL_OK)
  {
    Error_Handler();
  }

}

static void MX_SPI1_Init(void)
{

  /* SPI1 parameter configuration*/
  hspi1.Instance = SPI1;
  hspi1.Init.Mode = SPI_MODE_MASTER;
  hspi1.Init.Direction = SPI_DIRECTION_2LINES;
  hspi1.Init.DataSize = SPI_DATASIZE_4BIT;
  hspi1.Init.CLKPolarity = SPI_POLARITY_LOW;
  hspi1.Init.CLKPhase = SPI_PHASE_1EDGE;
  hspi1.Init.NSS = SPI_NSS_SOFT;
  hspi1.Init.BaudRatePrescaler = SPI_BAUDRATEPRESCALER_2;
  hspi1.Init.FirstBit = SPI_FIRSTBIT_MSB;
  hspi1.Init.TIMode = SPI_TIMODE_DISABLE;
  hspi1.Init.CRCCalculation = SPI_CRCCALCULATION_DISABLE;
  hspi1.Init.CRCPolynomial = 0x0;
  hspi1.Init.NSSPMode = SPI_NSS_PULSE_ENABLE;
  hspi1.Init.NSSPolarity = SPI_NSS_POLARITY_LOW;
  hspi1.Init.FifoThreshold = SPI_FIFO_THRESHOLD_01DATA;
  hspi1.Init.TxCRCInitializationPattern = SPI_CRC_INITIALIZATION_ALL_ZERO_PATTERN;
  hspi1.Init.RxCRCInitializationPattern = SPI_CRC_INITIALIZATION_ALL_ZERO_PATTERN;
  hspi1.Init.MasterSSIdleness = SPI_MASTER_SS_IDLENESS_00CYCLE;
  hspi1.Init.MasterInterDataIdleness = SPI_MASTER_INTERDATA_IDLENESS_00CYCLE;
  hspi1.Init.MasterReceiverAutoSusp = SPI_MASTER_RX_AUTOSUSP_DISABLE;
  hspi1.Init.MasterKeepIOState = SPI_MASTER_KEEP_IO_STATE_DISABLE;
  hspi1.Init.IOSwap = SPI_IO_SWAP_DISABLE;
  if (HAL_SPI_Init(&hspi1) != HAL_OK)
  {
    Error_Handler();
  }

}

static void MX_TIM2_Init(void)
{

  TIM_ClockConfigTypeDef sClockSourceConfig = {0};
  TIM_MasterConfigTypeDef sMasterConfig = {0};
  TIM_OC_InitTypeDef sConfigOC = {0};

  htim2.Instance = TIM2;
  htim2.Init.Prescaler = 0;
  htim2.Init.CounterMode = TIM_COUNTERMODE_UP;
  htim2.Init.Period = 6400;
  htim2.Init.ClockDivision = TIM_CLOCKDIVISION_DIV1;
  htim2.Init.AutoReloadPreload = TIM_AUTORELOAD_PRELOAD_DISABLE;
  if (HAL_TIM_Base_Init(&htim2) != HAL_OK)
  {
    Error_Handler();
  }
  sClockSourceConfig.ClockSource = TIM_CLOCKSOURCE_INTERNAL;
  if (HAL_TIM_ConfigClockSource(&htim2, &sClockSourceConfig) != HAL_OK)
  {
    Error_Handler();
  }
  if (HAL_TIM_PWM_Init(&htim2) != HAL_OK)
  {
    Error_Handler();
  }
  sMasterConfig.MasterOutputTrigger = TIM_TRGO_RESET;
  sMasterConfig.MasterSlaveMode = TIM_MASTERSLAVEMODE_DISABLE;
  if (HAL_TIMEx_MasterConfigSynchronization(&htim2, &sMasterConfig) != HAL_OK)
  {
    Error_Handler();
  }
  sConfigOC.OCMode = TIM_OCMODE_PWM1;
  sConfigOC.Pulse = 0;
  sConfigOC.OCPolarity = TIM_OCPOLARITY_HIGH;
  sConfigOC.OCFastMode = TIM_OCFAST_DISABLE;
  if (HAL_TIM_PWM_ConfigChannel(&htim2, &sConfigOC, TIM_CHANNEL_2) != HAL_OK)
  {
    Error_Handler();
  }
  if (HAL_TIM_PWM_ConfigChannel(&htim2, &sConfigOC, TIM_CHANNEL_4) != HAL_OK)
  {
    Error_Handler();
  }
  HAL_TIM_MspPostInit(&htim2);

}

static void MX_TIM3_Init(void)
{

  TIM_MasterConfigTypeDef sMasterConfig = {0};
  TIM_OC_InitTypeDef sConfigOC = {0};

  htim3.Instance = TIM3;
  htim3.Init.Prescaler = 0;
  htim3.Init.CounterMode = TIM_COUNTERMODE_UP;
  htim3.Init.Period = 6400;
  htim3.Init.ClockDivision = TIM_CLOCKDIVISION_DIV1;
  htim3.Init.AutoReloadPreload = TIM_AUTORELOAD_PRELOAD_DISABLE;
  if (HAL_TIM_PWM_Init(&htim3) != HAL_OK)
  {
    Error_Handler();
  }
  sMasterConfig.MasterOutputTrigger = TIM_TRGO_RESET;
  sMasterConfig.MasterSlaveMode = TIM_MASTERSLAVEMODE_DISABLE;
  if (HAL_TIMEx_MasterConfigSynchronization(&htim3, &sMasterConfig) != HAL_OK)
  {
    Error_Handler();
  }
  sConfigOC.OCMode = TIM_OCMODE_PWM1;
  sConfigOC.Pulse = 0;
  sConfigOC.OCPolarity = TIM_OCPOLARITY_HIGH;
  sConfigOC.OCFastMode = TIM_OCFAST_DISABLE;
  if (HAL_TIM_PWM_ConfigChannel(&htim3, &sConfigOC, TIM_CHANNEL_1) != HAL_OK)
  {
    Error_Handler();
  }
  if (HAL_TIM_PWM_ConfigChannel(&htim3, &sConfigOC, TIM_CHANNEL_2) != HAL_OK)
  {
    Error_Handler();
  }
  if (HAL_TIM_PWM_ConfigChannel(&htim3, &sConfigOC, TIM_CHANNEL_3) != HAL_OK)
  {
    Error_Handler();
  }
  if (HAL_TIM_PWM_ConfigChannel(&htim3, &sConfigOC, TIM_CHANNEL_4) != HAL_OK)
  {
    Error_Handler();
  }
  HAL_TIM_MspPostInit(&htim3);

}

static void MX_TIM4_Init(void)
{

  TIM_MasterConfigTypeDef sMasterConfig = {0};
  TIM_OC_InitTypeDef sConfigOC = {0};

  htim4.Instance = TIM4;
  htim4.Init.Prescaler = 0;
  htim4.Init.CounterMode = TIM_COUNTERMODE_UP;
  htim4.Init.Period = 6400;
  htim4.Init.ClockDivision = TIM_CLOCKDIVISION_DIV1;
  htim4.Init.AutoReloadPreload = TIM_AUTORELOAD_PRELOAD_DISABLE;
  if (HAL_TIM_PWM_Init(&htim4) != HAL_OK)
  {
    Error_Handler();
  }
  sMasterConfig.MasterOutputTrigger = TIM_TRGO_RESET;
  sMasterConfig.MasterSlaveMode = TIM_MASTERSLAVEMODE_DISABLE;
  if (HAL_TIMEx_MasterConfigSynchronization(&htim4, &sMasterConfig) != HAL_OK)
  {
    Error_Handler();
  }
  sConfigOC.OCMode = TIM_OCMODE_PWM1;
  sConfigOC.Pulse = 0;
  sConfigOC.OCPolarity = TIM_OCPOLARITY_HIGH;
  sConfigOC.OCFastMode = TIM_OCFAST_DISABLE;
  if (HAL_TIM_PWM_ConfigChannel(&htim4, &sConfigOC, TIM_CHANNEL_2) != HAL_OK)
  {
    Error_Handler();
  }
  if (HAL_TIM_PWM_ConfigChannel(&htim4, &sConfigOC, TIM_CHANNEL_3) != HAL_OK)
  {
    Error_Handler();
  }
  if (HAL_TIM_PWM_ConfigChannel(&htim4, &sConfigOC, TIM_CHANNEL_4) != HAL_OK)
  {
    Error_Handler();
  }
  HAL_TIM_MspPostInit(&htim4);

}

static void MX_TIM5_Init(void)
{

  TIM_MasterConfigTypeDef sMasterConfig = {0};
  TIM_OC_InitTypeDef sConfigOC = {0};

  htim5.Instance = TIM5;
  htim5.Init.Prescaler = 0;
  htim5.Init.CounterMode = TIM_COUNTERMODE_UP;
  htim5.Init.Period = 6400;
  htim5.Init.ClockDivision = TIM_CLOCKDIVISION_DIV1;
  htim5.Init.AutoReloadPreload = TIM_AUTORELOAD_PRELOAD_DISABLE;
  if (HAL_TIM_PWM_Init(&htim5) != HAL_OK)
  {
    Error_Handler();
  }
  sMasterConfig.MasterOutputTrigger = TIM_TRGO_RESET;
  sMasterConfig.MasterSlaveMode = TIM_MASTERSLAVEMODE_DISABLE;
  if (HAL_TIMEx_MasterConfigSynchronization(&htim5, &sMasterConfig) != HAL_OK)
  {
    Error_Handler();
  }
  sConfigOC.OCMode = TIM_OCMODE_PWM1;
  sConfigOC.Pulse = 0;
  sConfigOC.OCPolarity = TIM_OCPOLARITY_HIGH;
  sConfigOC.OCFastMode = TIM_OCFAST_DISABLE;
  if (HAL_TIM_PWM_ConfigChannel(&htim5, &sConfigOC, TIM_CHANNEL_1) != HAL_OK)
  {
    Error_Handler();
  }
  HAL_TIM_MspPostInit(&htim5);

}

static void MX_TIM8_Init(void)
{

  TIM_MasterConfigTypeDef sMasterConfig = {0};
  TIM_OC_InitTypeDef sConfigOC = {0};
  TIM_BreakDeadTimeConfigTypeDef sBreakDeadTimeConfig = {0};

  htim8.Instance = TIM8;
  htim8.Init.Prescaler = 0;
  htim8.Init.CounterMode = TIM_COUNTERMODE_UP;
  htim8.Init.Period = 6400;
  htim8.Init.ClockDivision = TIM_CLOCKDIVISION_DIV1;
  htim8.Init.RepetitionCounter = 0;
  htim8.Init.AutoReloadPreload = TIM_AUTORELOAD_PRELOAD_DISABLE;
  if (HAL_TIM_PWM_Init(&htim8) != HAL_OK)
  {
    Error_Handler();
  }
  sMasterConfig.MasterOutputTrigger = TIM_TRGO_RESET;
  sMasterConfig.MasterOutputTrigger2 = TIM_TRGO2_RESET;
  sMasterConfig.MasterSlaveMode = TIM_MASTERSLAVEMODE_DISABLE;
  if (HAL_TIMEx_MasterConfigSynchronization(&htim8, &sMasterConfig) != HAL_OK)
  {
    Error_Handler();
  }
  sConfigOC.OCMode = TIM_OCMODE_PWM1;
  sConfigOC.Pulse = 0;
  sConfigOC.OCPolarity = TIM_OCPOLARITY_HIGH;
  sConfigOC.OCNPolarity = TIM_OCNPOLARITY_HIGH;
  sConfigOC.OCFastMode = TIM_OCFAST_DISABLE;
  sConfigOC.OCIdleState = TIM_OCIDLESTATE_RESET;
  sConfigOC.OCNIdleState = TIM_OCNIDLESTATE_RESET;
  if (HAL_TIM_PWM_ConfigChannel(&htim8, &sConfigOC, TIM_CHANNEL_1) != HAL_OK)
  {
    Error_Handler();
  }
  if (HAL_TIM_PWM_ConfigChannel(&htim8, &sConfigOC, TIM_CHANNEL_2) != HAL_OK)
  {
    Error_Handler();
  }
  if (HAL_TIM_PWM_ConfigChannel(&htim8, &sConfigOC, TIM_CHANNEL_4) != HAL_OK)
  {
    Error_Handler();
  }
  sBreakDeadTimeConfig.OffStateRunMode = TIM_OSSR_DISABLE;
  sBreakDeadTimeConfig.OffStateIDLEMode = TIM_OSSI_DISABLE;
  sBreakDeadTimeConfig.LockLevel = TIM_LOCKLEVEL_OFF;
  sBreakDeadTimeConfig.DeadTime = 0;
  sBreakDeadTimeConfig.BreakState = TIM_BREAK_DISABLE;
  sBreakDeadTimeConfig.BreakPolarity = TIM_BREAKPOLARITY_HIGH;
  sBreakDeadTimeConfig.BreakFilter = 0;
  sBreakDeadTimeConfig.Break2State = TIM_BREAK2_DISABLE;
  sBreakDeadTimeConfig.Break2Polarity = TIM_BREAK2POLARITY_HIGH;
  sBreakDeadTimeConfig.Break2Filter = 0;
  sBreakDeadTimeConfig.AutomaticOutput = TIM_AUTOMATICOUTPUT_DISABLE;
  if (HAL_TIMEx_ConfigBreakDeadTime(&htim8, &sBreakDeadTimeConfig) != HAL_OK)
  {
    Error_Handler();
  }
  HAL_TIM_MspPostInit(&htim8);

}

static void MX_TIM12_Init(void)
{

  TIM_OC_InitTypeDef sConfigOC = {0};

  htim12.Instance = TIM12;
  htim12.Init.Prescaler = 0;
  htim12.Init.CounterMode = TIM_COUNTERMODE_UP;
  htim12.Init.Period = 6400;
  htim12.Init.ClockDivision = TIM_CLOCKDIVISION_DIV1;
  htim12.Init.AutoReloadPreload = TIM_AUTORELOAD_PRELOAD_DISABLE;
  if (HAL_TIM_PWM_Init(&htim12) != HAL_OK)
  {
    Error_Handler();
  }
  sConfigOC.OCMode = TIM_OCMODE_PWM1;
  sConfigOC.Pulse = 0;
  sConfigOC.OCPolarity = TIM_OCPOLARITY_HIGH;
  sConfigOC.OCFastMode = TIM_OCFAST_DISABLE;
  if (HAL_TIM_PWM_ConfigChannel(&htim12, &sConfigOC, TIM_CHANNEL_2) != HAL_OK)
  {
    Error_Handler();
  }
  HAL_TIM_MspPostInit(&htim12);

}

static void MX_UART4_Init(void)
{

  huart4.Instance = UART4;
  huart4.Init.BaudRate = 9600;
  huart4.Init.WordLength = UART_WORDLENGTH_8B;
  huart4.Init.StopBits = UART_STOPBITS_1;
  huart4.Init.Parity = UART_PARITY_NONE;
  huart4.Init.Mode = UART_MODE_TX_RX;
  huart4.Init.HwFlowCtl = UART_HWCONTROL_NONE;
  huart4.Init.OverSampling = UART_OVERSAMPLING_16;
  huart4.Init.OneBitSampling = UART_ONE_BIT_SAMPLE_DISABLE;
  huart4.Init.ClockPrescaler = UART_PRESCALER_DIV1;
  huart4.AdvancedInit.AdvFeatureInit = UART_ADVFEATURE_NO_INIT;
  if (HAL_UART_Init(&huart4) != HAL_OK)
  {
    Error_Handler();
  }
  if (HAL_UARTEx_SetTxFifoThreshold(&huart4, UART_TXFIFO_THRESHOLD_1_8) != HAL_OK)
  {
    Error_Handler();
  }
  if (HAL_UARTEx_SetRxFifoThreshold(&huart4, UART_RXFIFO_THRESHOLD_1_8) != HAL_OK)
  {
    Error_Handler();
  }
  if (HAL_UARTEx_DisableFifoMode(&huart4) != HAL_OK)
  {
    Error_Handler();
  }

}

static void MX_UART7_Init(void)
{

  huart7.Instance = UART7;
  huart7.Init.BaudRate = 19200;
  huart7.Init.WordLength = UART_WORDLENGTH_8B;
  huart7.Init.StopBits = UART_STOPBITS_1;
  huart7.Init.Parity = UART_PARITY_NONE;
  huart7.Init.Mode = UART_MODE_TX_RX;
  huart7.Init.HwFlowCtl = UART_HWCONTROL_NONE;
  huart7.Init.OverSampling = UART_OVERSAMPLING_16;
  huart7.Init.OneBitSampling = UART_ONE_BIT_SAMPLE_DISABLE;
  huart7.Init.ClockPrescaler = UART_PRESCALER_DIV1;
  huart7.AdvancedInit.AdvFeatureInit = UART_ADVFEATURE_NO_INIT;
  if (HAL_UART_Init(&huart7) != HAL_OK)
  {
    Error_Handler();
  }
  if (HAL_UARTEx_SetTxFifoThreshold(&huart7, UART_TXFIFO_THRESHOLD_1_8) != HAL_OK)
  {
    Error_Handler();
  }
  if (HAL_UARTEx_SetRxFifoThreshold(&huart7, UART_RXFIFO_THRESHOLD_1_8) != HAL_OK)
  {
    Error_Handler();
  }
  if (HAL_UARTEx_DisableFifoMode(&huart7) != HAL_OK)
  {
    Error_Handler();
  }

}

static void MX_UART8_Init(void)
{

  huart8.Instance = UART8;
  huart8.Init.BaudRate = 115200;
  huart8.Init.WordLength = UART_WORDLENGTH_8B;
  huart8.Init.StopBits = UART_STOPBITS_1;
  huart8.Init.Parity = UART_PARITY_NONE;
  huart8.Init.Mode = UART_MODE_TX_RX;
  huart8.Init.HwFlowCtl = UART_HWCONTROL_NONE;
  huart8.Init.OverSampling = UART_OVERSAMPLING_16;
  huart8.Init.OneBitSampling = UART_ONE_BIT_SAMPLE_DISABLE;
  huart8.Init.ClockPrescaler = UART_PRESCALER_DIV1;
  huart8.AdvancedInit.AdvFeatureInit = UART_ADVFEATURE_NO_INIT;
  if (HAL_HalfDuplex_Init(&huart8) != HAL_OK)
  {
    Error_Handler();
  }
  if (HAL_UARTEx_SetTxFifoThreshold(&huart8, UART_TXFIFO_THRESHOLD_1_8) != HAL_OK)
  {
    Error_Handler();
  }
  if (HAL_UARTEx_SetRxFifoThreshold(&huart8, UART_RXFIFO_THRESHOLD_1_8) != HAL_OK)
  {
    Error_Handler();
  }
  if (HAL_UARTEx_DisableFifoMode(&huart8) != HAL_OK)
  {
    Error_Handler();
  }

}

static void MX_USART1_UART_Init(void)
{

  huart1.Instance = USART1;
  huart1.Init.BaudRate = 115200;
  huart1.Init.WordLength = UART_WORDLENGTH_8B;
  huart1.Init.StopBits = UART_STOPBITS_1;
  huart1.Init.Parity = UART_PARITY_NONE;
  huart1.Init.Mode = UART_MODE_TX_RX;
  huart1.Init.HwFlowCtl = UART_HWCONTROL_RTS_CTS;
  huart1.Init.OverSampling = UART_OVERSAMPLING_16;
  huart1.Init.OneBitSampling = UART_ONE_BIT_SAMPLE_DISABLE;
  huart1.Init.ClockPrescaler = UART_PRESCALER_DIV1;
  huart1.AdvancedInit.AdvFeatureInit = UART_ADVFEATURE_NO_INIT;
  if (HAL_UART_Init(&huart1) != HAL_OK)
  {
    Error_Handler();
  }
  if (HAL_UARTEx_SetTxFifoThreshold(&huart1, UART_TXFIFO_THRESHOLD_1_8) != HAL_OK)
  {
    Error_Handler();
  }
  if (HAL_UARTEx_SetRxFifoThreshold(&huart1, UART_RXFIFO_THRESHOLD_1_8) != HAL_OK)
  {
    Error_Handler();
  }
  if (HAL_UARTEx_DisableFifoMode(&huart1) != HAL_OK)
  {
    Error_Handler();
  }

}

static void MX_USART3_UART_Init(void)
{

  huart3.Instance = USART3;
  huart3.Init.BaudRate = 115200;
  huart3.Init.WordLength = UART_WORDLENGTH_8B;
  huart3.Init.StopBits = UART_STOPBITS_1;
  huart3.Init.Parity = UART_PARITY_NONE;
  huart3.Init.Mode = UART_MODE_TX_RX;
  huart3.Init.HwFlowCtl = UART_HWCONTROL_NONE;
  huart3.Init.OverSampling = UART_OVERSAMPLING_16;
  huart3.Init.OneBitSampling = UART_ONE_BIT_SAMPLE_DISABLE;
  huart3.Init.ClockPrescaler = UART_PRESCALER_DIV1;
  huart3.AdvancedInit.AdvFeatureInit = UART_ADVFEATURE_NO_INIT;
  if (HAL_UART_Init(&huart3) != HAL_OK)
  {
    Error_Handler();
  }
  if (HAL_UARTEx_SetTxFifoThreshold(&huart3, UART_TXFIFO_THRESHOLD_1_8) != HAL_OK)
  {
    Error_Handler();
  }
  if (HAL_UARTEx_SetRxFifoThreshold(&huart3, UART_RXFIFO_THRESHOLD_1_8) != HAL_OK)
  {
    Error_Handler();
  }
  if (HAL_UARTEx_DisableFifoMode(&huart3) != HAL_OK)
  {
    Error_Handler();
  }

}

static void MX_GPIO_Init(void)
{
  GPIO_InitTypeDef GPIO_InitStruct = {0};

  /* GPIO Ports Clock Enable */
  __HAL_RCC_GPIOE_CLK_ENABLE();
  __HAL_RCC_GPIOC_CLK_ENABLE();
  __HAL_RCC_GPIOF_CLK_ENABLE();
  __HAL_RCC_GPIOH_CLK_ENABLE();
  __HAL_RCC_GPIOA_CLK_ENABLE();
  __HAL_RCC_GPIOB_CLK_ENABLE();
  __HAL_RCC_GPIOG_CLK_ENABLE();
  __HAL_RCC_GPIOD_CLK_ENABLE();

  /*Configure GPIO pin Output Level */
  HAL_GPIO_WritePin(GPIOE, BAT_MEAS_EN_Pin|LED1_EN_Pin|GPIO3_Pin|SENSE_O2_EN_Pin
                          |MOTOR2_EN_Pin|PRESS1_EN_Pin|MOTOR2_DIR_Pin|MOTOR3_DIR_Pin
                          |MOTOR2_STEP_Pin|MOTOR3_EN_Pin|PRESS5_EN_Pin, GPIO_PIN_RESET);

  /*Configure GPIO pin Output Level */
  HAL_GPIO_WritePin(GPIOF, BAT_CHARGE_EN_Pin|PRESS2_EN_Pin|PRESS4_EN_Pin|MOTOR4_EN_Pin
                          |MOTOR3_STEP_Pin|PRESS3_EN_Pin, GPIO_PIN_RESET);

  /*Configure GPIO pin Output Level */
  HAL_GPIO_WritePin(GPIOA, ALARM1_MED_Pin|BUZZ1_EN_Pin, GPIO_PIN_RESET);

  /*Configure GPIO pin Output Level */
  HAL_GPIO_WritePin(GPIOC, GPIO2_Pin|GPIO1_Pin|SER_CLK_Pin|SER_CLR_N_Pin
                          |SER_RCLK_Pin, GPIO_PIN_RESET);

  /*Configure GPIO pin Output Level */
  HAL_GPIO_WritePin(GPIOB, LD1_Pin|ALARM1_LOW_Pin|SER_IN_Pin, GPIO_PIN_RESET);

  /*Configure GPIO pin Output Level */
  HAL_GPIO_WritePin(GPIOD, MOTOR4_STEP_Pin|MOTOR1_STEP_Pin|MOTOR1_DIR_Pin|LTC4421_PWR_nDISABLE1_Pin
                          |LTC4421_PWR_nDISABLE2_Pin, GPIO_PIN_RESET);

  /*Configure GPIO pin Output Level */
  HAL_GPIO_WritePin(GPIOG, PRESS_VDD_EN_Pin|I2C1_RESET_Pin|I2C2_RESET_Pin|MOTOR1_EN_Pin
                          |PRESS6_EN_Pin|LED3_EN_Pin|ALARM1_HIGH_Pin|PRESSX_EN_Pin
                          |MOTOR4_DIR_Pin|LED2_EN_Pin, GPIO_PIN_RESET);

  /*Configure GPIO pins : SET_MANUAL_BREATH_Pin VSYS_3V3_PGOOD_Pin VSYS_5V0_PGOOD_Pin SET_LOCK_Pin */
  GPIO_InitStruct.Pin = SET_MANUAL_BREATH_Pin|VSYS_3V3_PGOOD_Pin|VSYS_5V0_PGOOD_Pin|SET_LOCK_Pin;
  GPIO_InitStruct.Mode = GPIO_MODE_INPUT;
  GPIO_InitStruct.Pull = GPIO_NOPULL;
  HAL_GPIO_Init(GPIOE, &GPIO_InitStruct);

  /*Configure GPIO pins : BAT_MEAS_EN_Pin LED1_EN_Pin GPIO3_Pin SENSE_O2_EN_Pin
                           MOTOR2_EN_Pin PRESS1_EN_Pin MOTOR2_DIR_Pin MOTOR3_DIR_Pin
                           MOTOR2_STEP_Pin MOTOR3_EN_Pin PRESS5_EN_Pin */
  GPIO_InitStruct.Pin = BAT_MEAS_EN_Pin|LED1_EN_Pin|GPIO3_Pin|SENSE_O2_EN_Pin
                          |MOTOR2_EN_Pin|PRESS1_EN_Pin|MOTOR2_DIR_Pin|MOTOR3_DIR_Pin
                          |MOTOR2_STEP_Pin|MOTOR3_EN_Pin|PRESS5_EN_Pin;
  GPIO_InitStruct.Mode = GPIO_MODE_OUTPUT_PP;
  GPIO_InitStruct.Pull = GPIO_NOPULL;
  GPIO_InitStruct.Speed = GPIO_SPEED_FREQ_LOW;
  HAL_GPIO_Init(GPIOE, &GPIO_InitStruct);

  /*Configure GPIO pin : B1_Pin */
  GPIO_InitStruct.Pin = B1_Pin;
  GPIO_InitStruct.Mode = GPIO_MODE_INPUT;
  GPIO_InitStruct.Pull = GPIO_NOPULL;
  HAL_GPIO_Init(B1_GPIO_Port, &GPIO_InitStruct);

  /*Configure GPIO pins : LTC4421_PWR_nFAULT2_Pin LTC4421_PWR_nFAULT1_Pin */
  GPIO_InitStruct.Pin = LTC4421_PWR_nFAULT2_Pin|LTC4421_PWR_nFAULT1_Pin;
  GPIO_InitStruct.Mode = GPIO_MODE_INPUT;
  GPIO_InitStruct.Pull = GPIO_NOPULL;
  HAL_GPIO_Init(GPIOF, &GPIO_InitStruct);

  /*Configure GPIO pins : BAT_CHARGE_EN_Pin PRESS2_EN_Pin PRESS4_EN_Pin MOTOR4_EN_Pin
                           MOTOR3_STEP_Pin PRESS3_EN_Pin */
  GPIO_InitStruct.Pin = BAT_CHARGE_EN_Pin|PRESS2_EN_Pin|PRESS4_EN_Pin|MOTOR4_EN_Pin
                          |MOTOR3_STEP_Pin|PRESS3_EN_Pin;
  GPIO_InitStruct.Mode = GPIO_MODE_OUTPUT_PP;
  GPIO_InitStruct.Pull = GPIO_NOPULL;
  GPIO_InitStruct.Speed = GPIO_SPEED_FREQ_LOW;
  HAL_GPIO_Init(GPIOF, &GPIO_InitStruct);

  /*Configure GPIO pins : ALARM1_MED_Pin BUZZ1_EN_Pin */
  GPIO_InitStruct.Pin = ALARM1_MED_Pin|BUZZ1_EN_Pin;
  GPIO_InitStruct.Mode = GPIO_MODE_OUTPUT_PP;
  GPIO_InitStruct.Pull = GPIO_NOPULL;
  GPIO_InitStruct.Speed = GPIO_SPEED_FREQ_LOW;
  HAL_GPIO_Init(GPIOA, &GPIO_InitStruct);

  /*Configure GPIO pins : GPIO2_Pin GPIO1_Pin SER_CLK_Pin SER_CLR_N_Pin
                           SER_RCLK_Pin */
  GPIO_InitStruct.Pin = GPIO2_Pin|GPIO1_Pin|SER_CLK_Pin|SER_CLR_N_Pin
                          |SER_RCLK_Pin;
  GPIO_InitStruct.Mode = GPIO_MODE_OUTPUT_PP;
  GPIO_InitStruct.Pull = GPIO_NOPULL;
  GPIO_InitStruct.Speed = GPIO_SPEED_FREQ_LOW;
  HAL_GPIO_Init(GPIOC, &GPIO_InitStruct);

  /*Configure GPIO pins : LD1_Pin ALARM1_LOW_Pin SER_IN_Pin */
  GPIO_InitStruct.Pin = LD1_Pin|ALARM1_LOW_Pin|SER_IN_Pin;
  GPIO_InitStruct.Mode = GPIO_MODE_OUTPUT_PP;
  GPIO_InitStruct.Pull = GPIO_NOPULL;
  GPIO_InitStruct.Speed = GPIO_SPEED_FREQ_LOW;
  HAL_GPIO_Init(GPIOB, &GPIO_InitStruct);

  /*Configure GPIO pin : SET_PWR_ON_OFF_Pin */
  GPIO_InitStruct.Pin = SET_PWR_ON_OFF_Pin;
  GPIO_InitStruct.Mode = GPIO_MODE_INPUT;
  GPIO_InitStruct.Pull = GPIO_NOPULL;
  HAL_GPIO_Init(SET_PWR_ON_OFF_GPIO_Port, &GPIO_InitStruct);

  /*Configure GPIO pins : LTC4421_PWR_nCH1_Pin LTC4421_PWR_nCH2_Pin SET_ALARM_EN_Pin SET_100_O2_Pin */
  GPIO_InitStruct.Pin = LTC4421_PWR_nCH1_Pin|LTC4421_PWR_nCH2_Pin|SET_ALARM_EN_Pin|SET_100_O2_Pin;
  GPIO_InitStruct.Mode = GPIO_MODE_INPUT;
  GPIO_InitStruct.Pull = GPIO_NOPULL;
  HAL_GPIO_Init(GPIOG, &GPIO_InitStruct);

  /*Configure GPIO pins : MOTOR4_STEP_Pin MOTOR1_STEP_Pin MOTOR1_DIR_Pin LTC4421_PWR_nDISABLE1_Pin
                           LTC4421_PWR_nDISABLE2_Pin */
  GPIO_InitStruct.Pin = MOTOR4_STEP_Pin|MOTOR1_STEP_Pin|MOTOR1_DIR_Pin|LTC4421_PWR_nDISABLE1_Pin
                          |LTC4421_PWR_nDISABLE2_Pin;
  GPIO_InitStruct.Mode = GPIO_MODE_OUTPUT_PP;
  GPIO_InitStruct.Pull = GPIO_NOPULL;
  GPIO_InitStruct.Speed = GPIO_SPEED_FREQ_LOW;
  HAL_GPIO_Init(GPIOD, &GPIO_InitStruct);

  /*Configure GPIO pins : PRESS_VDD_EN_Pin I2C1_RESET_Pin I2C2_RESET_Pin MOTOR1_EN_Pin
                           PRESS6_EN_Pin LED3_EN_Pin ALARM1_HIGH_Pin PRESSX_EN_Pin
                           MOTOR4_DIR_Pin LED2_EN_Pin */
  GPIO_InitStruct.Pin = PRESS_VDD_EN_Pin|I2C1_RESET_Pin|I2C2_RESET_Pin|MOTOR1_EN_Pin
                          |PRESS6_EN_Pin|LED3_EN_Pin|ALARM1_HIGH_Pin|PRESSX_EN_Pin
                          |MOTOR4_DIR_Pin|LED2_EN_Pin;
  GPIO_InitStruct.Mode = GPIO_MODE_OUTPUT_PP;
  GPIO_InitStruct.Pull = GPIO_NOPULL;
  GPIO_InitStruct.Speed = GPIO_SPEED_FREQ_LOW;
  HAL_GPIO_Init(GPIOG, &GPIO_InitStruct);

  /*Configure GPIO pins : LTC4421_PWR_nVALID1_Pin LTC4421_PWR_nVALID2_Pin */
  GPIO_InitStruct.Pin = LTC4421_PWR_nVALID1_Pin|LTC4421_PWR_nVALID2_Pin;
  GPIO_InitStruct.Mode = GPIO_MODE_INPUT;
  GPIO_InitStruct.Pull = GPIO_NOPULL;
  HAL_GPIO_Init(GPIOD, &GPIO_InitStruct);

}

void Error_Handler(void)
{
}

#ifdef  USE_FULL_ASSERT
/**
  * @brief  Reports the name of the source file and the source line number
  *         where the assert_param error has occurred.
  * @param  file: pointer to the source file name
  * @param  line: assert_param error line source number
  * @retval None
  */
void assert_failed(uint8_t *file, uint32_t line)
{
  /* USER CODE BEGIN 6 */
  /* User can add his own implementation to report the file name and line
     number,
     tex: printf("Wrong parameters value: file %s on line %d\r\n", file, line)
   */
  /* USER CODE END 6 */
}
#endif /* USE_FULL_ASSERT */

/************************ (C) COPYRIGHT STMicroelectronics *****END OF FILE****/
